AUTOSAR XML (schema 00046)
package /ComponentTypes
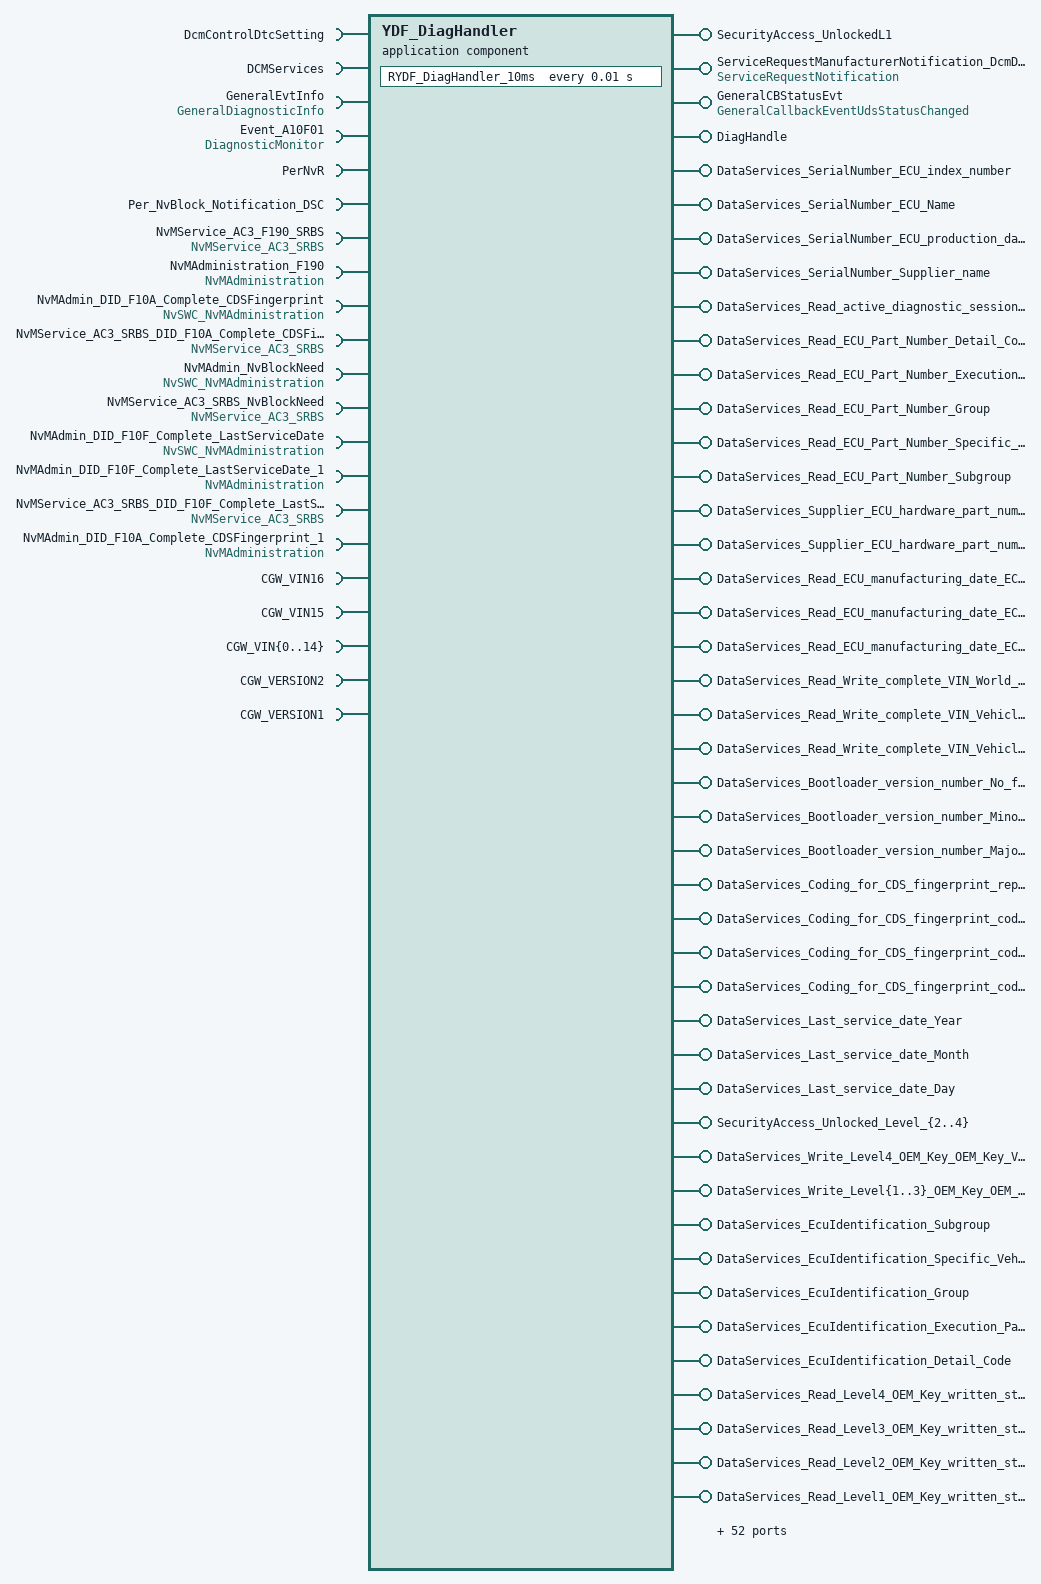
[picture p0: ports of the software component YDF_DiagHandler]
  application sw component type YDF_DiagHandler
    require port DcmControlDtcSetting: mode-switch-receiver-com-spec=DcmControlDtcSetting, required-interface=DcmControlDtcSetting
    require port DCMServices: required-interface=DCMServices
      required-com-specs:
        GetActiveProtocol
        GetSesCtrlType
        ResetToDefaultSession
        GetSecurityLevel
        SetActiveDiagnostic
        GetRequestKind
    provide port SecurityAccess_UnlockedL1: provided-com-specs=[{operation=GetSeed, queue-length=1}, {operation=CompareKey, queue-length=1}], provided-interface=SecurityAccess_UnlockedL1
    provide port ServiceRequestManufacturerNotification_DcmDslServiceRequestManufacturerNotification: provided-com-specs=[{operation=Indication, queue-length=1}, {operation=Confirmation, queue-length=1}], provided-interface=ServiceRequestNotification
    provide port GeneralCBStatusEvt: server-com-spec{operation=GeneralCallbackEventUdsStatusChanged, queue-length=1}, provided-interface=GeneralCallbackEventUdsStatusChanged
    require port GeneralEvtInfo: required-interface=GeneralDiagnosticInfo
      required-com-specs:
        GetEventUdsStatus
        GetEventStatus
        GetEventFailed
        GetEventTested
        GetDTCOfEvent
        GetFaultDetectionCounter
        GetEventFreezeFrameDataEx
        GetEventExtendedDataRecordEx
        GetEventEnableCondition
        GetDebouncingOfEvent
        GetMonitorStatus
    require port Event_A10F01: required-interface=DiagnosticMonitor
      required-com-specs:
        SetEventStatus
        ResetEventStatus
        ResetEventDebounceStatus
        GetEventUdsStatus
        GetEventStatus
        GetEventFailed
        GetEventTested
        GetDTCOfEvent
        GetFaultDetectionCounter
        GetEventFreezeFrameDataEx
        GetEventExtendedDataRecordEx
    provide port DiagHandle: provided-com-specs=[{operation=SetEventSts, queue-length=1}, {operation=GetEventSts, queue-length=1}], provided-interface=DiagHandle
    require port PerNvR: required-com-specs=[WriteRequest, ReadRequest], required-interface=PerNvR
    require port Per_NvBlock_Notification_DSC: nonqueued-receiver-com-spec{data-element=WriteComplete, enable-update=true, filter=data-filter-type=ALWAYS, init-value=0}, required-interface=Per_NvBlock_Notification_DSC
    28 x provide port:
      DataServices_SerialNumber_ECU_index_number: provided-com-specs=[{operation=ConditionCheckRead, queue-length=1}, {operation=ReadData, queue-length=1}], provided-interface=DataServices_SerialNumber_ECU_index_number
      DataServices_SerialNumber_ECU_Name: provided-com-specs=[{operation=ConditionCheckRead, queue-length=1}, {operation=ReadData, queue-length=1}], provided-interface=DataServices_SerialNumber_ECU_Name
      DataServices_SerialNumber_ECU_production_date_in_DD_MM_YY_format: provided-com-specs=[{operation=ConditionCheckRead, queue-length=1}, {operation=ReadData, queue-length=1}], provided-interface=DataServices_SerialNumber_ECU_production_date_in_DD_MM_YY_format
      DataServices_SerialNumber_Supplier_name: provided-com-specs=[{operation=ConditionCheckRead, queue-length=1}, {operation=ReadData, queue-length=1}], provided-interface=DataServices_SerialNumber_Supplier_name
      DataServices_Read_active_diagnostic_session_Active_diagnostic_session: provided-com-specs=[{operation=ConditionCheckRead, queue-length=1}, {operation=ReadData, queue-length=1}], provided-interface=DataServices_Read_active_diagnostic_session_Active_diagnostic_session
      DataServices_Read_ECU_Part_Number_Detail_Code: provided-com-specs=[{operation=ConditionCheckRead, queue-length=1}, {operation=ReadData, queue-length=1}], provided-interface=DataServices_Read_ECU_Part_Number_Detail_Code
      DataServices_Read_ECU_Part_Number_Execution_Package: provided-com-specs=[{operation=ConditionCheckRead, queue-length=1}, {operation=ReadData, queue-length=1}], provided-interface=DataServices_Read_ECU_Part_Number_Execution_Package
      DataServices_Read_ECU_Part_Number_Group: provided-com-specs=[{operation=ConditionCheckRead, queue-length=1}, {operation=ReadData, queue-length=1}], provided-interface=DataServices_Read_ECU_Part_Number_Group
      DataServices_Read_ECU_Part_Number_Specific_Vehicle_Code_WMI: provided-com-specs=[{operation=ConditionCheckRead, queue-length=1}, {operation=ReadData, queue-length=1}], provided-interface=DataServices_Read_ECU_Part_Number_Specific_Vehicle_Code_WMI
      DataServices_Read_ECU_Part_Number_Subgroup: provided-com-specs=[{operation=ConditionCheckRead, queue-length=1}, {operation=ReadData, queue-length=1}], provided-interface=DataServices_Read_ECU_Part_Number_Subgroup
      DataServices_Supplier_ECU_hardware_part_number_Major_release: provided-com-specs=[{operation=ConditionCheckRead, queue-length=1}, {operation=ReadData, queue-length=1}], provided-interface=DataServices_Supplier_ECU_hardware_part_number_Major_release
      DataServices_Supplier_ECU_hardware_part_number_Changes_in_electronic_components_level: provided-com-specs=[{operation=ConditionCheckRead, queue-length=1}, {operation=ReadData, queue-length=1}], provided-interface=DataServices_Supplier_ECU_hardware_part_number_Changes_in_electronic_components_level
      DataServices_Read_ECU_manufacturing_date_ECU_Manufacturing_Date_Day: provided-com-specs=[{operation=ConditionCheckRead, queue-length=1}, {operation=ReadData, queue-length=1}], provided-interface=DataServices_Read_ECU_manufacturing_date_ECU_Manufacturing_Date_Day
      DataServices_Read_ECU_manufacturing_date_ECU_Manufacturing_Date_Month: provided-com-specs=[{operation=ConditionCheckRead, queue-length=1}, {operation=ReadData, queue-length=1}], provided-interface=DataServices_Read_ECU_manufacturing_date_ECU_Manufacturing_Date_Month
      DataServices_Read_ECU_manufacturing_date_ECU_Manufacturing_Date_Year: provided-com-specs=[{operation=ConditionCheckRead, queue-length=1}, {operation=ReadData, queue-length=1}], provided-interface=DataServices_Read_ECU_manufacturing_date_ECU_Manufacturing_Date_Year
      DataServices_Read_Write_complete_VIN_World_Manufacturers_Identification: provided-interface=DataServices_Read_Write_complete_VIN_World_Manufacturers_Identification
        provided-com-specs:
          operation=WriteData, queue-length=1
          operation=ConditionCheckRead, queue-length=1
          operation=ReadData, queue-length=1
      DataServices_Read_Write_complete_VIN_Vehicle_Identification_Section: provided-interface=DataServices_Read_Write_complete_VIN_Vehicle_Identification_Section
        provided-com-specs:
          operation=WriteData, queue-length=1
          operation=ConditionCheckRead, queue-length=1
          operation=ReadData, queue-length=1
      DataServices_Read_Write_complete_VIN_Vehicle_Description_Section: provided-interface=DataServices_Read_Write_complete_VIN_Vehicle_Description_Section
        provided-com-specs:
          operation=WriteData, queue-length=1
          operation=ConditionCheckRead, queue-length=1
          operation=ReadData, queue-length=1
      DataServices_Bootloader_version_number_No_functional_content_change: provided-com-specs=[{operation=ConditionCheckRead, queue-length=1}, {operation=ReadData, queue-length=1}], provided-interface=DataServices_Bootloader_version_number_No_functional_content_change
      DataServices_Bootloader_version_number_Minor_release: provided-com-specs=[{operation=ConditionCheckRead, queue-length=1}, {operation=ReadData, queue-length=1}], provided-interface=DataServices_Bootloader_version_number_Minor_release
      DataServices_Bootloader_version_number_Major_release: provided-com-specs=[{operation=ConditionCheckRead, queue-length=1}, {operation=ReadData, queue-length=1}], provided-interface=DataServices_Bootloader_version_number_Major_release
      DataServices_Coding_for_CDS_fingerprint_repairShopCodeorTesterSerialNumber_byte_1_27_MSB: provided-interface=DataServices_Coding_for_CDS_fingerprint_repairShopCodeorTesterSerialNumber_byte_1_27_MSB
        provided-com-specs:
          operation=WriteData, queue-length=1
          operation=ConditionCheckRead, queue-length=1
          operation=ReadData, queue-length=1
      DataServices_Coding_for_CDS_fingerprint_codingDate_byte_3_DD: provided-interface=DataServices_Coding_for_CDS_fingerprint_codingDate_byte_3_DD
        provided-com-specs:
          operation=WriteData, queue-length=1
          operation=ConditionCheckRead, queue-length=1
          operation=ReadData, queue-length=1
      DataServices_Coding_for_CDS_fingerprint_codingDate_byte_2_MM: provided-interface=DataServices_Coding_for_CDS_fingerprint_codingDate_byte_2_MM
        provided-com-specs:
          operation=WriteData, queue-length=1
          operation=ConditionCheckRead, queue-length=1
          operation=ReadData, queue-length=1
      DataServices_Coding_for_CDS_fingerprint_codingDate_byte_1_YY: provided-interface=DataServices_Coding_for_CDS_fingerprint_codingDate_byte_1_YY
        provided-com-specs:
          operation=WriteData, queue-length=1
          operation=ConditionCheckRead, queue-length=1
          operation=ReadData, queue-length=1
      DataServices_Last_service_date_Year: provided-interface=DataServices_Last_service_date_Year
        provided-com-specs:
          operation=WriteData, queue-length=1
          operation=ConditionCheckRead, queue-length=1
          operation=ReadData, queue-length=1
      DataServices_Last_service_date_Month: provided-interface=DataServices_Last_service_date_Month
        provided-com-specs:
          operation=WriteData, queue-length=1
          operation=ConditionCheckRead, queue-length=1
          operation=ReadData, queue-length=1
      DataServices_Last_service_date_Day: provided-interface=DataServices_Last_service_date_Day
        provided-com-specs:
          operation=WriteData, queue-length=1
          operation=ConditionCheckRead, queue-length=1
          operation=ReadData, queue-length=1
    10 x require port:
      NvMService_AC3_F190_SRBS: required-com-specs=[WriteBlock, SetRamBlockStatus, ReadBlock, InvalidateNvBlock, GetErrorStatus, EraseBlock], required-interface=NvMService_AC3_SRBS
      NvMAdministration_F190: client-com-spec=SetBlockProtection, required-interface=NvMAdministration
      NvMAdmin_DID_F10A_Complete_CDSFingerprint: client-com-spec=SetBlockProtection, required-interface=NvSWC_NvMAdministration
      NvMService_AC3_SRBS_DID_F10A_Complete_CDSFingerprint: required-com-specs=[WriteBlock, SetRamBlockStatus, ReadBlock, InvalidateNvBlock, GetErrorStatus, EraseBlock], required-interface=NvMService_AC3_SRBS
      NvMAdmin_NvBlockNeed: client-com-spec=SetBlockProtection, required-interface=NvSWC_NvMAdministration
      NvMService_AC3_SRBS_NvBlockNeed: required-com-specs=[WriteBlock, SetRamBlockStatus, ReadBlock, InvalidateNvBlock, GetErrorStatus, EraseBlock], required-interface=NvMService_AC3_SRBS
      NvMAdmin_DID_F10F_Complete_LastServiceDate: client-com-spec=SetBlockProtection, required-interface=NvSWC_NvMAdministration
      NvMAdmin_DID_F10F_Complete_LastServiceDate_1: client-com-spec=SetBlockProtection, required-interface=NvMAdministration
      NvMService_AC3_SRBS_DID_F10F_Complete_LastServiceDate: required-com-specs=[WriteBlock, SetRamBlockStatus, ReadBlock, InvalidateNvBlock, GetErrorStatus, EraseBlock], required-interface=NvMService_AC3_SRBS
      NvMAdmin_DID_F10A_Complete_CDSFingerprint_1: client-com-spec=SetBlockProtection, required-interface=NvMAdministration
    62 x provide port:
      SecurityAccess_Unlocked_Level_{2..4}: provided-com-specs=[{operation=CompareKey, queue-length=1}, {operation=GetSeed, queue-length=1}], provided-interface=SecurityAccess_Unlocked_Level_{2..4}
      DataServices_Write_Level4_OEM_Key_OEM_Key_Value: server-com-spec{operation=WriteData, queue-length=1}, provided-interface=DataServices_Write_Level4_OEM_Key_OEM_Key_Value
      DataServices_Write_Level{1..3}_OEM_Key_OEM_Key_Value: server-com-spec{operation=WriteData, queue-length=1}, provided-interface=DataServices_Write_Level{1..3}_OEM_Key_OEM_Key_Value
      DataServices_EcuIdentification_Subgroup: provided-interface=DataServices_EcuIdentification_Subgroup
        provided-com-specs:
          operation=WriteData, queue-length=1
          operation=ConditionCheckRead, queue-length=1
          operation=ReadData, queue-length=1
      DataServices_EcuIdentification_Specific_Vehicle_Code_WMI: provided-interface=DataServices_EcuIdentification_Specific_Vehicle_Code_WMI
        provided-com-specs:
          operation=WriteData, queue-length=1
          operation=ConditionCheckRead, queue-length=1
          operation=ReadData, queue-length=1
      DataServices_EcuIdentification_Group: provided-interface=DataServices_EcuIdentification_Group
        provided-com-specs:
          operation=WriteData, queue-length=1
          operation=ConditionCheckRead, queue-length=1
          operation=ReadData, queue-length=1
      DataServices_EcuIdentification_Execution_Package: provided-interface=DataServices_EcuIdentification_Execution_Package
        provided-com-specs:
          operation=WriteData, queue-length=1
          operation=ConditionCheckRead, queue-length=1
          operation=ReadData, queue-length=1
      DataServices_EcuIdentification_Detail_Code: provided-interface=DataServices_EcuIdentification_Detail_Code
        provided-com-specs:
          operation=WriteData, queue-length=1
          operation=ConditionCheckRead, queue-length=1
          operation=ReadData, queue-length=1
      DataServices_Read_Level4_OEM_Key_written_status_Read_Level4_OEM_Key_rewrite_counter: provided-com-specs=[{operation=ConditionCheckRead, queue-length=1}, {operation=ReadData, queue-length=1}], provided-interface=DataServices_Read_Level4_OEM_Key_written_status_Read_Level4_OEM_Key_rewrite_counter
      DataServices_Read_Level3_OEM_Key_written_status_Read_Level3_OEM_Key_rewrite_counter: provided-com-specs=[{operation=ConditionCheckRead, queue-length=1}, {operation=ReadData, queue-length=1}], provided-interface=DataServices_Read_Level3_OEM_Key_written_status_Read_Level3_OEM_Key_rewrite_counter
      DataServices_Read_Level2_OEM_Key_written_status_Read_Level2_OEM_Key_rewrite_counter: provided-com-specs=[{operation=ConditionCheckRead, queue-length=1}, {operation=ReadData, queue-length=1}], provided-interface=DataServices_Read_Level2_OEM_Key_written_status_Read_Level2_OEM_Key_rewrite_counter
      DataServices_Read_Level1_OEM_Key_written_status_Read_Level1_OEM_Key_rewrite_counter: provided-com-specs=[{operation=ConditionCheckRead, queue-length=1}, {operation=ReadData, queue-length=1}], provided-interface=DataServices_Read_Level1_OEM_Key_written_status_Read_Level1_OEM_Key_rewrite_counter
      DataServices_Read_Vehicle_Security_related_events_Brute_Force_UDS_0x27_servic_Event_occurance_time_Year_5: provided-com-specs=[{operation=ConditionCheckRead, queue-length=1}, {operation=ReadData, queue-length=1}], provided-interface=DataServices_Read_Vehicle_Security_related_events_Brute_Force_UDS_0x27_servic_Event_occurance_time_Year_5
      DataServices_Read_Vehicle_Security_related_events_Brute_Force_UDS_0x27_servic_Event_occurance_time_Year_4: provided-com-specs=[{operation=ConditionCheckRead, queue-length=1}, {operation=ReadData, queue-length=1}], provided-interface=DataServices_Read_Vehicle_Security_related_events_Brute_Force_UDS_0x27_servic_Event_occurance_time_Year_4
      DataServices_Read_Vehicle_Security_related_events_Brute_Force_UDS_0x27_servic_Event_occurance_time_Year_3: provided-com-specs=[{operation=ConditionCheckRead, queue-length=1}, {operation=ReadData, queue-length=1}], provided-interface=DataServices_Read_Vehicle_Security_related_events_Brute_Force_UDS_0x27_servic_Event_occurance_time_Year_3
      DataServices_Read_Vehicle_Security_related_events_Brute_Force_UDS_0x27_servic_Event_occurance_time_Year_2: provided-com-specs=[{operation=ConditionCheckRead, queue-length=1}, {operation=ReadData, queue-length=1}], provided-interface=DataServices_Read_Vehicle_Security_related_events_Brute_Force_UDS_0x27_servic_Event_occurance_time_Year_2
      DataServices_Read_Vehicle_Security_related_events_Brute_Force_UDS_0x27_servic_Event_occurance_time_Year_1: provided-com-specs=[{operation=ConditionCheckRead, queue-length=1}, {operation=ReadData, queue-length=1}], provided-interface=DataServices_Read_Vehicle_Security_related_events_Brute_Force_UDS_0x27_servic_Event_occurance_time_Year_1
      DataServices_Read_Vehicle_Security_related_events_Brute_Force_UDS_0x27_servic_Event_occurance_time_Month_5: provided-com-specs=[{operation=ConditionCheckRead, queue-length=1}, {operation=ReadData, queue-length=1}], provided-interface=DataServices_Read_Vehicle_Security_related_events_Brute_Force_UDS_0x27_servic_Event_occurance_time_Month_5
      DataServices_Read_Vehicle_Security_related_events_Brute_Force_UDS_0x27_servic_Event_occurance_time_Month_4: provided-com-specs=[{operation=ConditionCheckRead, queue-length=1}, {operation=ReadData, queue-length=1}], provided-interface=DataServices_Read_Vehicle_Security_related_events_Brute_Force_UDS_0x27_servic_Event_occurance_time_Month_4
      DataServices_Read_Vehicle_Security_related_events_Brute_Force_UDS_0x27_servic_Event_occurance_time_Month_3: provided-com-specs=[{operation=ConditionCheckRead, queue-length=1}, {operation=ReadData, queue-length=1}], provided-interface=DataServices_Read_Vehicle_Security_related_events_Brute_Force_UDS_0x27_servic_Event_occurance_time_Month_3
      DataServices_Read_Vehicle_Security_related_events_Brute_Force_UDS_0x27_servic_Event_occurance_time_Month_2: provided-com-specs=[{operation=ConditionCheckRead, queue-length=1}, {operation=ReadData, queue-length=1}], provided-interface=DataServices_Read_Vehicle_Security_related_events_Brute_Force_UDS_0x27_servic_Event_occurance_time_Month_2
      DataServices_Read_Vehicle_Security_related_events_Brute_Force_UDS_0x27_servic_Event_occurance_time_Month_1: provided-com-specs=[{operation=ConditionCheckRead, queue-length=1}, {operation=ReadData, queue-length=1}], provided-interface=DataServices_Read_Vehicle_Security_related_events_Brute_Force_UDS_0x27_servic_Event_occurance_time_Month_1
      DataServices_Read_Vehicle_Security_related_events_Brute_Force_UDS_0x27_servic_Event_occurance_time_Day_5: provided-com-specs=[{operation=ConditionCheckRead, queue-length=1}, {operation=ReadData, queue-length=1}], provided-interface=DataServices_Read_Vehicle_Security_related_events_Brute_Force_UDS_0x27_servic_Event_occurance_time_Day_5
      DataServices_Read_Vehicle_Security_related_events_Brute_Force_UDS_0x27_servic_Event_occurance_time_Day_4: provided-com-specs=[{operation=ConditionCheckRead, queue-length=1}, {operation=ReadData, queue-length=1}], provided-interface=DataServices_Read_Vehicle_Security_related_events_Brute_Force_UDS_0x27_servic_Event_occurance_time_Day_4
      DataServices_Read_Vehicle_Security_related_events_Brute_Force_UDS_0x27_servic_Event_occurance_time_Day_3: provided-com-specs=[{operation=ConditionCheckRead, queue-length=1}, {operation=ReadData, queue-length=1}], provided-interface=DataServices_Read_Vehicle_Security_related_events_Brute_Force_UDS_0x27_servic_Event_occurance_time_Day_3
      DataServices_Read_Vehicle_Security_related_events_Brute_Force_UDS_0x27_servic_Event_occurance_time_Day_2: provided-com-specs=[{operation=ConditionCheckRead, queue-length=1}, {operation=ReadData, queue-length=1}], provided-interface=DataServices_Read_Vehicle_Security_related_events_Brute_Force_UDS_0x27_servic_Event_occurance_time_Day_2
      DataServices_Read_Vehicle_Security_related_events_Brute_Force_UDS_0x27_servic_Event_occurance_time_Day_1: provided-com-specs=[{operation=ConditionCheckRead, queue-length=1}, {operation=ReadData, queue-length=1}], provided-interface=DataServices_Read_Vehicle_Security_related_events_Brute_Force_UDS_0x27_servic_Event_occurance_time_Day_1
      DataServices_Read_Vehicle_Security_related_events_Brute_Force_UDS_0x27_servic_Brute_Force_UDS_0x27_service_Event_occurr_0DEE2FAA: provided-com-specs=[{operation=ConditionCheckRead, queue-length=1}, {operation=ReadData, queue-length=1}], provided-interface=DataServices_Read_Vehicle_Security_related_events_Brute_Force_UDS_0x27_servic_Brute_Force_UDS_0x27_service_Event_occurr_0DEE2FAA
      DataServices_Read_Vehicle_Security_related_events_Brute_Force_UDS_0x27_servic_Brute_Force_UDS_0x27_service_5: provided-com-specs=[{operation=ConditionCheckRead, queue-length=1}, {operation=ReadData, queue-length=1}], provided-interface=DataServices_Read_Vehicle_Security_related_events_Brute_Force_UDS_0x27_servic_Brute_Force_UDS_0x27_service_5
      DataServices_Read_Vehicle_Security_related_events_Brute_Force_UDS_0x27_servic_Brute_Force_UDS_0x27_service_4: provided-com-specs=[{operation=ConditionCheckRead, queue-length=1}, {operation=ReadData, queue-length=1}], provided-interface=DataServices_Read_Vehicle_Security_related_events_Brute_Force_UDS_0x27_servic_Brute_Force_UDS_0x27_service_4
      DataServices_Read_Vehicle_Security_related_events_Brute_Force_UDS_0x27_servic_Brute_Force_UDS_0x27_service_3: provided-com-specs=[{operation=ConditionCheckRead, queue-length=1}, {operation=ReadData, queue-length=1}], provided-interface=DataServices_Read_Vehicle_Security_related_events_Brute_Force_UDS_0x27_servic_Brute_Force_UDS_0x27_service_3
      DataServices_Read_Vehicle_Security_related_events_Brute_Force_UDS_0x27_servic_Brute_Force_UDS_0x27_service_2: provided-com-specs=[{operation=ConditionCheckRead, queue-length=1}, {operation=ReadData, queue-length=1}], provided-interface=DataServices_Read_Vehicle_Security_related_events_Brute_Force_UDS_0x27_servic_Brute_Force_UDS_0x27_service_2
      DataServices_Read_Vehicle_Security_related_events_Brute_Force_UDS_0x27_servic_Brute_Force_UDS_0x27_service_1: provided-com-specs=[{operation=ConditionCheckRead, queue-length=1}, {operation=ReadData, queue-length=1}], provided-interface=DataServices_Read_Vehicle_Security_related_events_Brute_Force_UDS_0x27_servic_Brute_Force_UDS_0x27_service_1
      DataServices_Read_Vehicle_Security_related_events_Software_configuration_inte_Software_configuration_integrity_check_fa_B04CEA39: provided-com-specs=[{operation=ConditionCheckRead, queue-length=1}, {operation=ReadData, queue-length=1}], provided-interface=DataServices_Read_Vehicle_Security_related_events_Software_configuration_inte_Software_configuration_integrity_check_fa_B04CEA39
      DataServices_Read_Vehicle_Security_related_events_Software_configuration_inte_Software_configuration_integrity_check_5: provided-com-specs=[{operation=ConditionCheckRead, queue-length=1}, {operation=ReadData, queue-length=1}], provided-interface=DataServices_Read_Vehicle_Security_related_events_Software_configuration_inte_Software_configuration_integrity_check_5
      DataServices_Read_Vehicle_Security_related_events_Software_configuration_inte_Software_configuration_integrity_check_4: provided-com-specs=[{operation=ConditionCheckRead, queue-length=1}, {operation=ReadData, queue-length=1}], provided-interface=DataServices_Read_Vehicle_Security_related_events_Software_configuration_inte_Software_configuration_integrity_check_4
      DataServices_Read_Vehicle_Security_related_events_Software_configuration_inte_Software_configuration_integrity_check_3: provided-com-specs=[{operation=ConditionCheckRead, queue-length=1}, {operation=ReadData, queue-length=1}], provided-interface=DataServices_Read_Vehicle_Security_related_events_Software_configuration_inte_Software_configuration_integrity_check_3
      DataServices_Read_Vehicle_Security_related_events_Software_configuration_inte_Software_configuration_integrity_check_2: provided-com-specs=[{operation=ConditionCheckRead, queue-length=1}, {operation=ReadData, queue-length=1}], provided-interface=DataServices_Read_Vehicle_Security_related_events_Software_configuration_inte_Software_configuration_integrity_check_2
      DataServices_Read_Vehicle_Security_related_events_Software_configuration_inte_Software_configuration_integrity_check_1: provided-com-specs=[{operation=ConditionCheckRead, queue-length=1}, {operation=ReadData, queue-length=1}], provided-interface=DataServices_Read_Vehicle_Security_related_events_Software_configuration_inte_Software_configuration_integrity_check_1
      DataServices_Read_Vehicle_Security_related_events_Software_configuration_inte_Event_occurance_time_Year_5: provided-com-specs=[{operation=ConditionCheckRead, queue-length=1}, {operation=ReadData, queue-length=1}], provided-interface=DataServices_Read_Vehicle_Security_related_events_Software_configuration_inte_Event_occurance_time_Year_5
      DataServices_Read_Vehicle_Security_related_events_Software_configuration_inte_Event_occurance_time_Year_4: provided-com-specs=[{operation=ConditionCheckRead, queue-length=1}, {operation=ReadData, queue-length=1}], provided-interface=DataServices_Read_Vehicle_Security_related_events_Software_configuration_inte_Event_occurance_time_Year_4
      DataServices_Read_Vehicle_Security_related_events_Software_configuration_inte_Event_occurance_time_Year_3: provided-com-specs=[{operation=ConditionCheckRead, queue-length=1}, {operation=ReadData, queue-length=1}], provided-interface=DataServices_Read_Vehicle_Security_related_events_Software_configuration_inte_Event_occurance_time_Year_3
      DataServices_Read_Vehicle_Security_related_events_Software_configuration_inte_Event_occurance_time_Year_2: provided-com-specs=[{operation=ConditionCheckRead, queue-length=1}, {operation=ReadData, queue-length=1}], provided-interface=DataServices_Read_Vehicle_Security_related_events_Software_configuration_inte_Event_occurance_time_Year_2
      DataServices_Read_Vehicle_Security_related_events_Software_configuration_inte_Event_occurance_time_Year_1: provided-com-specs=[{operation=ConditionCheckRead, queue-length=1}, {operation=ReadData, queue-length=1}], provided-interface=DataServices_Read_Vehicle_Security_related_events_Software_configuration_inte_Event_occurance_time_Year_1
      DataServices_Read_Vehicle_Security_related_events_Software_configuration_inte_Event_occurance_time_Month_5: provided-com-specs=[{operation=ConditionCheckRead, queue-length=1}, {operation=ReadData, queue-length=1}], provided-interface=DataServices_Read_Vehicle_Security_related_events_Software_configuration_inte_Event_occurance_time_Month_5
      DataServices_Read_Vehicle_Security_related_events_Software_configuration_inte_Event_occurance_time_Month_4: provided-com-specs=[{operation=ConditionCheckRead, queue-length=1}, {operation=ReadData, queue-length=1}], provided-interface=DataServices_Read_Vehicle_Security_related_events_Software_configuration_inte_Event_occurance_time_Month_4
      DataServices_Read_Vehicle_Security_related_events_Software_configuration_inte_Event_occurance_time_Month_3: provided-com-specs=[{operation=ConditionCheckRead, queue-length=1}, {operation=ReadData, queue-length=1}], provided-interface=DataServices_Read_Vehicle_Security_related_events_Software_configuration_inte_Event_occurance_time_Month_3
      DataServices_Read_Vehicle_Security_related_events_Software_configuration_inte_Event_occurance_time_Month_2: provided-com-specs=[{operation=ConditionCheckRead, queue-length=1}, {operation=ReadData, queue-length=1}], provided-interface=DataServices_Read_Vehicle_Security_related_events_Software_configuration_inte_Event_occurance_time_Month_2
      DataServices_Read_Vehicle_Security_related_events_Software_configuration_inte_Event_occurance_time_Month_1: provided-com-specs=[{operation=ConditionCheckRead, queue-length=1}, {operation=ReadData, queue-length=1}], provided-interface=DataServices_Read_Vehicle_Security_related_events_Software_configuration_inte_Event_occurance_time_Month_1
      DataServices_Read_Vehicle_Security_related_events_Software_configuration_inte_Event_occurance_time_Day_5: provided-com-specs=[{operation=ConditionCheckRead, queue-length=1}, {operation=ReadData, queue-length=1}], provided-interface=DataServices_Read_Vehicle_Security_related_events_Software_configuration_inte_Event_occurance_time_Day_5
      DataServices_Read_Vehicle_Security_related_events_Software_configuration_inte_Event_occurance_time_Day_4: provided-com-specs=[{operation=ConditionCheckRead, queue-length=1}, {operation=ReadData, queue-length=1}], provided-interface=DataServices_Read_Vehicle_Security_related_events_Software_configuration_inte_Event_occurance_time_Day_4
      DataServices_Read_Vehicle_Security_related_events_Software_configuration_inte_Event_occurance_time_Day_3: provided-com-specs=[{operation=ConditionCheckRead, queue-length=1}, {operation=ReadData, queue-length=1}], provided-interface=DataServices_Read_Vehicle_Security_related_events_Software_configuration_inte_Event_occurance_time_Day_3
      DataServices_Read_Vehicle_Security_related_events_Software_configuration_inte_Event_occurance_time_Day_2: provided-com-specs=[{operation=ConditionCheckRead, queue-length=1}, {operation=ReadData, queue-length=1}], provided-interface=DataServices_Read_Vehicle_Security_related_events_Software_configuration_inte_Event_occurance_time_Day_2
      DataServices_Read_Vehicle_Security_related_events_Software_configuration_inte_Event_occurance_time_Day_1: provided-com-specs=[{operation=ConditionCheckRead, queue-length=1}, {operation=ReadData, queue-length=1}], provided-interface=DataServices_Read_Vehicle_Security_related_events_Software_configuration_inte_Event_occurance_time_Day_1
      DataServices_Write_Level4_OEM_Key_CRC: server-com-spec{operation=WriteData, queue-length=1}, provided-interface=DataServices_Write_Level4_OEM_Key_CRC
      DataServices_Write_Level3_OEM_Key_CRC: server-com-spec{operation=WriteData, queue-length=1}, provided-interface=DataServices_Write_Level3_OEM_Key_CRC
      DataServices_Write_Level2_OEM_Key_CRC: server-com-spec{operation=WriteData, queue-length=1}, provided-interface=DataServices_Write_Level2_OEM_Key_CRC
      DataServices_Write_Level1_OEM_Key_CRC: server-com-spec{operation=WriteData, queue-length=1}, provided-interface=DataServices_Write_Level1_OEM_Key_CRC
    19 x require port:
      CGW_VIN16: nonqueued-receiver-com-spec{data-element=CGW_VIN16, filter=data-filter-type=ALWAYS, init-value=0}, required-interface=CGW_VIN16
      CGW_VIN15: nonqueued-receiver-com-spec{data-element=CGW_VIN15, init-value=0}, required-interface=CGW_VIN15
      CGW_VIN{0..14}: nonqueued-receiver-com-spec{data-element=CGW_VIN{0..14}, init-value=0}, required-interface=CGW_VIN{0..14}
      CGW_VERSION2: nonqueued-receiver-com-spec{data-element=CGW_VERSION2, filter=data-filter-type=ALWAYS, init-value=0}, required-interface=CGW_VERSION2
      CGW_VERSION1: nonqueued-receiver-com-spec{data-element=CGW_VERSION1, filter=data-filter-type=ALWAYS, init-value=0}, required-interface=CGW_VERSION1
    6 x provide port, all with provided-com-specs=[{operation=ConditionCheckRead, queue-length=1}, {operation=ReadData, queue-length=1}]:
      DataServices_BSW_version_number_Major_release: provided-interface=DataServices_BSW_version_number_Major_release
      DataServices_BSW_version_number_Minor_release: provided-interface=DataServices_BSW_version_number_Minor_release
      DataServices_BSW_version_number_No_functional_content_change: provided-interface=DataServices_BSW_version_number_No_functional_content_change
      DataServices_DevelopmentData_Country_code: provided-interface=DataServices_DevelopmentData_Country_code
      DataServices_DevelopmentData_Supplier_family_code: provided-interface=DataServices_DevelopmentData_Supplier_family_code
      DataServices_DevelopmentData_Supplier_code: provided-interface=DataServices_DevelopmentData_Supplier_code
    behavior YDF_DiagHandler_InternalBehavior
      init event RYDF_DiagHandler_InitEvent: start-on-event=RYDF_DiagHandler_Init
      timing event TMT_RYDF_DiagHandler_10ms: start-on-event=RYDF_DiagHandler_10ms, period=0.01
      206 x operation invoked event:
        OIT_SecurityAccess_UnlockedL1_CompareKey_SecurityAccess_UnlockedL1_CompareKey: start-on-event=SecurityAccess_UnlockedL1_CompareKey, operation=SecurityAccess_UnlockedL1.CompareKey
        OIT_SecurityAccess_UnlockedL1_GetSeed_SecurityAccess_UnlockedL1_GetSeed: start-on-event=SecurityAccess_UnlockedL1_GetSeed, operation=SecurityAccess_UnlockedL1.GetSeed
        OIT_ServiceRequestManufacturerNotification_DcmDslServiceRequestManufacturerNotification_Confirmation_ServiceRequestManufB5A5EF03: start-on-event=ServiceRequestManufacturerNotification_DcmDslServiceRequestManufacturerNotification_Confirmation, operation=ServiceRequestManufacturerNotification_DcmDslServiceRequestManufacturerNotification.Confirmation
        OIT_ServiceRequestManufacturerNotification_DcmDslServiceRequestManufacturerNotification_Indication_ServiceRequestManufac0656CBDD: start-on-event=ServiceRequestManufacturerNotification_DcmDslServiceRequestManufacturerNotification_Indication, operation=ServiceRequestManufacturerNotification_DcmDslServiceRequestManufacturerNotification.Indication
        OIT_GeneralCBStatusEvt_GeneralCallbackEventUdsStatusChanged_GeneralCBStatusEvt_GeneralCallbackEventUdsStatusChanged: start-on-event=GeneralCBStatusEvt_GeneralCallbackEventUdsStatusChanged, operation=GeneralCBStatusEvt.GeneralCallbackEventUdsStatusChanged
        OIT_DiagHandle_SetEventSts_DiagHandle_SetEventSts: start-on-event=DiagHandle_SetEventSts, operation=DiagHandle.SetEventSts
        OIT_DiagHandle_GetEventSts_DiagHandle_GetEventSts: start-on-event=DiagHandle_GetEventSts, operation=DiagHandle.GetEventSts
        OIT_DataServices_SerialNumber_ECU_Name_ConditionCheckRead_DataServices_SerialNumber_ECU_Name_ConditionCheckRead: start-on-event=DataServices_SerialNumber_ECU_Name_ConditionCheckRead, operation=DataServices_SerialNumber_ECU_Name.ConditionCheckRead
        OIT_DataServices_SerialNumber_ECU_Name_ReadData_DataServices_SerialNumber_ECU_Name_ReadData: start-on-event=DataServices_SerialNumber_ECU_Name_ReadData, operation=DataServices_SerialNumber_ECU_Name.ReadData
        OIT_DataServices_SerialNumber_Supplier_name_ConditionCheckRead_DataServices_SerialNumber_Supplier_name_ConditionCheckRead: start-on-event=DataServices_SerialNumber_Supplier_name_ConditionCheckRead, operation=DataServices_SerialNumber_Supplier_name.ConditionCheckRead
        OIT_DataServices_SerialNumber_Supplier_name_ReadData_DataServices_SerialNumber_Supplier_name_ReadData: start-on-event=DataServices_SerialNumber_Supplier_name_ReadData, operation=DataServices_SerialNumber_Supplier_name.ReadData
        OIT_DataServices_SerialNumber_ECU_production_date_in_DD_MM_YY_format_ConditionCheckRead_DataServices_SerialNumber_ECU_pr44FAFC85: start-on-event=DataServices_SerialNumber_ECU_production_date_in_DD_MM_YY_format_ConditionCheckRead, operation=DataServices_SerialNumber_ECU_production_date_in_DD_MM_YY_format.ConditionCheckRead
        OIT_DataServices_SerialNumber_ECU_production_date_in_DD_MM_YY_format_ReadData_DataServices_SerialNumber_ECU_production_d2FB83547: start-on-event=DataServices_SerialNumber_ECU_production_date_in_DD_MM_YY_format_ReadData, operation=DataServices_SerialNumber_ECU_production_date_in_DD_MM_YY_format.ReadData
        OIT_DataServices_SerialNumber_ECU_index_number_ConditionCheckRead_DataServices_SerialNumber_ECU_index_number_ConditionCheckRead: start-on-event=DataServices_SerialNumber_ECU_index_number_ConditionCheckRead, operation=DataServices_SerialNumber_ECU_index_number.ConditionCheckRead
        OIT_DataServices_SerialNumber_ECU_index_number_ReadData_DataServices_SerialNumber_ECU_index_number_ReadData: start-on-event=DataServices_SerialNumber_ECU_index_number_ReadData, operation=DataServices_SerialNumber_ECU_index_number.ReadData
        OIT_DataServices_Read_active_diagnostic_session_Active_diagnostic_session_ConditionCheckRead_DataServices_Read_active_diB49FB7AF: start-on-event=DataServices_Read_active_diagnostic_session_Active_diagnostic_session_ConditionCheckRead, operation=DataServices_Read_active_diagnostic_session_Active_diagnostic_session.ConditionCheckRead
        OIT_DataServices_Read_active_diagnostic_session_Active_diagnostic_session_ReadData_DataServices_Read_active_diagnostic_s46D8753B: start-on-event=DataServices_Read_active_diagnostic_session_Active_diagnostic_session_ReadData, operation=DataServices_Read_active_diagnostic_session_Active_diagnostic_session.ReadData
        OIT_DataServices_Read_ECU_Part_Number_Subgroup_ConditionCheckRead_DataServices_Read_ECU_Part_Number_Subgroup_ConditionCheckRead: start-on-event=DataServices_Read_ECU_Part_Number_Subgroup_ConditionCheckRead, operation=DataServices_Read_ECU_Part_Number_Subgroup.ConditionCheckRead
        OIT_DataServices_Read_ECU_Part_Number_Subgroup_ReadData_DataServices_Read_ECU_Part_Number_Subgroup_ReadData: start-on-event=DataServices_Read_ECU_Part_Number_Subgroup_ReadData, operation=DataServices_Read_ECU_Part_Number_Subgroup.ReadData
        OIT_DataServices_Read_ECU_Part_Number_Specific_Vehicle_Code_WMI_ConditionCheckRead_DataServices_Read_ECU_Part_Number_Spe426E84EB: start-on-event=DataServices_Read_ECU_Part_Number_Specific_Vehicle_Code_WMI_ConditionCheckRead, operation=DataServices_Read_ECU_Part_Number_Specific_Vehicle_Code_WMI.ConditionCheckRead
        OIT_DataServices_Read_ECU_Part_Number_Specific_Vehicle_Code_WMI_ReadData_DataServices_Read_ECU_Part_Number_Specific_Vehi316D5894: start-on-event=DataServices_Read_ECU_Part_Number_Specific_Vehicle_Code_WMI_ReadData, operation=DataServices_Read_ECU_Part_Number_Specific_Vehicle_Code_WMI.ReadData
        OIT_DataServices_Read_ECU_Part_Number_Detail_Code_ConditionCheckRead_DataServices_Read_ECU_Part_Number_Detail_Code_CondiF64CCC53: start-on-event=DataServices_Read_ECU_Part_Number_Detail_Code_ConditionCheckRead, operation=DataServices_Read_ECU_Part_Number_Detail_Code.ConditionCheckRead
        OIT_DataServices_Read_ECU_Part_Number_Detail_Code_ReadData_DataServices_Read_ECU_Part_Number_Detail_Code_ReadData: start-on-event=DataServices_Read_ECU_Part_Number_Detail_Code_ReadData, operation=DataServices_Read_ECU_Part_Number_Detail_Code.ReadData
        OIT_DataServices_Read_ECU_Part_Number_Execution_Package_ConditionCheckRead_DataServices_Read_ECU_Part_Number_Execution_P90DFECBE: start-on-event=DataServices_Read_ECU_Part_Number_Execution_Package_ConditionCheckRead, operation=DataServices_Read_ECU_Part_Number_Execution_Package.ConditionCheckRead
        OIT_DataServices_Read_ECU_Part_Number_Execution_Package_ReadData_DataServices_Read_ECU_Part_Number_Execution_Package_ReadData: start-on-event=DataServices_Read_ECU_Part_Number_Execution_Package_ReadData, operation=DataServices_Read_ECU_Part_Number_Execution_Package.ReadData
        OIT_DataServices_Read_ECU_Part_Number_Group_ConditionCheckRead_DataServices_Read_ECU_Part_Number_Group_ConditionCheckRead: start-on-event=DataServices_Read_ECU_Part_Number_Group_ConditionCheckRead, operation=DataServices_Read_ECU_Part_Number_Group.ConditionCheckRead
        OIT_DataServices_Read_ECU_Part_Number_Group_ReadData_DataServices_Read_ECU_Part_Number_Group_ReadData: start-on-event=DataServices_Read_ECU_Part_Number_Group_ReadData, operation=DataServices_Read_ECU_Part_Number_Group.ReadData
        OIT_DataServices_Supplier_ECU_hardware_part_number_Major_release_ConditionCheckRead_DataServices_Supplier_ECU_hardware_p96918959: start-on-event=DataServices_Supplier_ECU_hardware_part_number_Major_release_ConditionCheckRead, operation=DataServices_Supplier_ECU_hardware_part_number_Major_release.ConditionCheckRead
        OIT_DataServices_Supplier_ECU_hardware_part_number_Major_release_ReadData_DataServices_Supplier_ECU_hardware_part_number59738653: start-on-event=DataServices_Supplier_ECU_hardware_part_number_Major_release_ReadData, operation=DataServices_Supplier_ECU_hardware_part_number_Major_release.ReadData
        OIT_DataServices_Supplier_ECU_hardware_part_number_Changes_in_electronic_components_level_ConditionCheckRead_DataServiceF0611B9D: start-on-event=DataServices_Supplier_ECU_hardware_part_number_Changes_in_electronic_components_level_ConditionCheckRead, operation=DataServices_Supplier_ECU_hardware_part_number_Changes_in_electronic_components_level.ConditionCheckRead
        OIT_DataServices_Supplier_ECU_hardware_part_number_Changes_in_electronic_components_level_ReadData_DataServices_Supplier2940180F: start-on-event=DataServices_Supplier_ECU_hardware_part_number_Changes_in_electronic_components_level_ReadData, operation=DataServices_Supplier_ECU_hardware_part_number_Changes_in_electronic_components_level.ReadData
        OIT_DataServices_Read_ECU_manufacturing_date_ECU_Manufacturing_Date_Day_ConditionCheckRead_DataServices_Read_ECU_manufac9EC8DA1F: start-on-event=DataServices_Read_ECU_manufacturing_date_ECU_Manufacturing_Date_Day_ConditionCheckRead, operation=DataServices_Read_ECU_manufacturing_date_ECU_Manufacturing_Date_Day.ConditionCheckRead
        OIT_DataServices_Read_ECU_manufacturing_date_ECU_Manufacturing_Date_Day_ReadData_DataServices_Read_ECU_manufacturing_dat60D2E64F: start-on-event=DataServices_Read_ECU_manufacturing_date_ECU_Manufacturing_Date_Day_ReadData, operation=DataServices_Read_ECU_manufacturing_date_ECU_Manufacturing_Date_Day.ReadData
        OIT_DataServices_Read_ECU_manufacturing_date_ECU_Manufacturing_Date_Month_ConditionCheckRead_DataServices_Read_ECU_manuf213660AB: start-on-event=DataServices_Read_ECU_manufacturing_date_ECU_Manufacturing_Date_Month_ConditionCheckRead, operation=DataServices_Read_ECU_manufacturing_date_ECU_Manufacturing_Date_Month.ConditionCheckRead
        OIT_DataServices_Read_ECU_manufacturing_date_ECU_Manufacturing_Date_Month_ReadData_DataServices_Read_ECU_manufacturing_dF4BA3661: start-on-event=DataServices_Read_ECU_manufacturing_date_ECU_Manufacturing_Date_Month_ReadData, operation=DataServices_Read_ECU_manufacturing_date_ECU_Manufacturing_Date_Month.ReadData
        OIT_DataServices_Read_ECU_manufacturing_date_ECU_Manufacturing_Date_Year_ConditionCheckRead_DataServices_Read_ECU_manufa93305012: start-on-event=DataServices_Read_ECU_manufacturing_date_ECU_Manufacturing_Date_Year_ConditionCheckRead, operation=DataServices_Read_ECU_manufacturing_date_ECU_Manufacturing_Date_Year.ConditionCheckRead
        OIT_DataServices_Read_ECU_manufacturing_date_ECU_Manufacturing_Date_Year_ReadData_DataServices_Read_ECU_manufacturing_da075A8D33: start-on-event=DataServices_Read_ECU_manufacturing_date_ECU_Manufacturing_Date_Year_ReadData, operation=DataServices_Read_ECU_manufacturing_date_ECU_Manufacturing_Date_Year.ReadData
        OIT_DataServices_Read_Write_complete_VIN_Vehicle_Identification_Section_WriteData_DataServices_Read_Write_complete_VIN_VD525E295: start-on-event=DataServices_Read_Write_complete_VIN_Vehicle_Identification_Section_WriteData, operation=DataServices_Read_Write_complete_VIN_Vehicle_Identification_Section.WriteData
        OIT_DataServices_Read_Write_complete_VIN_Vehicle_Identification_Section_ConditionCheckRead_DataServices_Read_Write_compl1E42063A: start-on-event=DataServices_Read_Write_complete_VIN_Vehicle_Identification_Section_ConditionCheckRead, operation=DataServices_Read_Write_complete_VIN_Vehicle_Identification_Section.ConditionCheckRead
        OIT_DataServices_Read_Write_complete_VIN_Vehicle_Identification_Section_ReadData_DataServices_Read_Write_complete_VIN_VeCBA606E0: start-on-event=DataServices_Read_Write_complete_VIN_Vehicle_Identification_Section_ReadData, operation=DataServices_Read_Write_complete_VIN_Vehicle_Identification_Section.ReadData
        OIT_DataServices_Read_Write_complete_VIN_Vehicle_Description_Section_WriteData_DataServices_Read_Write_complete_VIN_Vehi3D5B2B2D: start-on-event=DataServices_Read_Write_complete_VIN_Vehicle_Description_Section_WriteData, operation=DataServices_Read_Write_complete_VIN_Vehicle_Description_Section.WriteData
        OIT_DataServices_Read_Write_complete_VIN_Vehicle_Description_Section_ConditionCheckRead_DataServices_Read_Write_complete95F8F646: start-on-event=DataServices_Read_Write_complete_VIN_Vehicle_Description_Section_ConditionCheckRead, operation=DataServices_Read_Write_complete_VIN_Vehicle_Description_Section.ConditionCheckRead
        OIT_DataServices_Read_Write_complete_VIN_Vehicle_Description_Section_ReadData_DataServices_Read_Write_complete_VIN_Vehic41F3C89C: start-on-event=DataServices_Read_Write_complete_VIN_Vehicle_Description_Section_ReadData, operation=DataServices_Read_Write_complete_VIN_Vehicle_Description_Section.ReadData
        OIT_DataServices_Read_Write_complete_VIN_World_Manufacturers_Identification_WriteData_DataServices_Read_Write_complete_VC79B143F: start-on-event=DataServices_Read_Write_complete_VIN_World_Manufacturers_Identification_WriteData, operation=DataServices_Read_Write_complete_VIN_World_Manufacturers_Identification.WriteData
        OIT_DataServices_Read_Write_complete_VIN_World_Manufacturers_Identification_ConditionCheckRead_DataServices_Read_Write_c794DF9F7: start-on-event=DataServices_Read_Write_complete_VIN_World_Manufacturers_Identification_ConditionCheckRead, operation=DataServices_Read_Write_complete_VIN_World_Manufacturers_Identification.ConditionCheckRead
        OIT_DataServices_Read_Write_complete_VIN_World_Manufacturers_Identification_ReadData_DataServices_Read_Write_complete_VI4EEA54AE: start-on-event=DataServices_Read_Write_complete_VIN_World_Manufacturers_Identification_ReadData, operation=DataServices_Read_Write_complete_VIN_World_Manufacturers_Identification.ReadData
        OIT_DataServices_Bootloader_version_number_Major_release_ConditionCheckRead_DataServices_Bootloader_version_number_MajorFB9C4A83: start-on-event=DataServices_Bootloader_version_number_Major_release_ConditionCheckRead, operation=DataServices_Bootloader_version_number_Major_release.ConditionCheckRead
        OIT_DataServices_Bootloader_version_number_Major_release_ReadData_DataServices_Bootloader_version_number_Major_release_ReadData: start-on-event=DataServices_Bootloader_version_number_Major_release_ReadData, operation=DataServices_Bootloader_version_number_Major_release.ReadData
        OIT_DataServices_Bootloader_version_number_No_functional_content_change_ConditionCheckRead_DataServices_Bootloader_versiC8D761B4: start-on-event=DataServices_Bootloader_version_number_No_functional_content_change_ConditionCheckRead, operation=DataServices_Bootloader_version_number_No_functional_content_change.ConditionCheckRead
        OIT_DataServices_Bootloader_version_number_No_functional_content_change_ReadData_DataServices_Bootloader_version_number_89B9F87D: start-on-event=DataServices_Bootloader_version_number_No_functional_content_change_ReadData, operation=DataServices_Bootloader_version_number_No_functional_content_change.ReadData
        OIT_DataServices_Bootloader_version_number_Minor_release_ConditionCheckRead_DataServices_Bootloader_version_number_Minor8DCEBD84: start-on-event=DataServices_Bootloader_version_number_Minor_release_ConditionCheckRead, operation=DataServices_Bootloader_version_number_Minor_release.ConditionCheckRead
        OIT_DataServices_Bootloader_version_number_Minor_release_ReadData_DataServices_Bootloader_version_number_Minor_release_ReadData: start-on-event=DataServices_Bootloader_version_number_Minor_release_ReadData, operation=DataServices_Bootloader_version_number_Minor_release.ReadData
        OIT_DataServices_Coding_for_CDS_fingerprint_codingDate_byte_1_YY_WriteData_DataServices_Coding_for_CDS_fingerprint_codinD669CD8A: start-on-event=DataServices_Coding_for_CDS_fingerprint_codingDate_byte_1_YY_WriteData, operation=DataServices_Coding_for_CDS_fingerprint_codingDate_byte_1_YY.WriteData
        OIT_DataServices_Coding_for_CDS_fingerprint_codingDate_byte_1_YY_ConditionCheckRead_DataServices_Coding_for_CDS_fingerpr8BC391BA: start-on-event=DataServices_Coding_for_CDS_fingerprint_codingDate_byte_1_YY_ConditionCheckRead, operation=DataServices_Coding_for_CDS_fingerprint_codingDate_byte_1_YY.ConditionCheckRead
        OIT_DataServices_Coding_for_CDS_fingerprint_codingDate_byte_1_YY_ReadData_DataServices_Coding_for_CDS_fingerprint_coding2B4017FD: start-on-event=DataServices_Coding_for_CDS_fingerprint_codingDate_byte_1_YY_ReadData, operation=DataServices_Coding_for_CDS_fingerprint_codingDate_byte_1_YY.ReadData
        OIT_DataServices_Coding_for_CDS_fingerprint_codingDate_byte_3_DD_WriteData_DataServices_Coding_for_CDS_fingerprint_codin1BE9EBC8: start-on-event=DataServices_Coding_for_CDS_fingerprint_codingDate_byte_3_DD_WriteData, operation=DataServices_Coding_for_CDS_fingerprint_codingDate_byte_3_DD.WriteData
        OIT_DataServices_Coding_for_CDS_fingerprint_codingDate_byte_3_DD_ConditionCheckRead_DataServices_Coding_for_CDS_fingerpr60774A27: start-on-event=DataServices_Coding_for_CDS_fingerprint_codingDate_byte_3_DD_ConditionCheckRead, operation=DataServices_Coding_for_CDS_fingerprint_codingDate_byte_3_DD.ConditionCheckRead
        OIT_DataServices_Coding_for_CDS_fingerprint_codingDate_byte_3_DD_ReadData_DataServices_Coding_for_CDS_fingerprint_codingD7AEC0B7: start-on-event=DataServices_Coding_for_CDS_fingerprint_codingDate_byte_3_DD_ReadData, operation=DataServices_Coding_for_CDS_fingerprint_codingDate_byte_3_DD.ReadData
        OIT_DataServices_Coding_for_CDS_fingerprint_repairShopCodeorTesterSerialNumber_byte_1_27_MSB_WriteData_DataServices_Codi63C9ABC8: start-on-event=DataServices_Coding_for_CDS_fingerprint_repairShopCodeorTesterSerialNumber_byte_1_27_MSB_WriteData, operation=DataServices_Coding_for_CDS_fingerprint_repairShopCodeorTesterSerialNumber_byte_1_27_MSB.WriteData
        OIT_DataServices_Coding_for_CDS_fingerprint_repairShopCodeorTesterSerialNumber_byte_1_27_MSB_ConditionCheckRead_DataServ02BB341A: start-on-event=DataServices_Coding_for_CDS_fingerprint_repairShopCodeorTesterSerialNumber_byte_1_27_MSB_ConditionCheckRead, operation=DataServices_Coding_for_CDS_fingerprint_repairShopCodeorTesterSerialNumber_byte_1_27_MSB.ConditionCheckRead
        OIT_DataServices_Coding_for_CDS_fingerprint_repairShopCodeorTesterSerialNumber_byte_1_27_MSB_ReadData_DataServices_Codin48C6C15A: start-on-event=DataServices_Coding_for_CDS_fingerprint_repairShopCodeorTesterSerialNumber_byte_1_27_MSB_ReadData, operation=DataServices_Coding_for_CDS_fingerprint_repairShopCodeorTesterSerialNumber_byte_1_27_MSB.ReadData
        OIT_DataServices_Coding_for_CDS_fingerprint_codingDate_byte_2_MM_WriteData_DataServices_Coding_for_CDS_fingerprint_codin6AD9550D: start-on-event=DataServices_Coding_for_CDS_fingerprint_codingDate_byte_2_MM_WriteData, operation=DataServices_Coding_for_CDS_fingerprint_codingDate_byte_2_MM.WriteData
        OIT_DataServices_Coding_for_CDS_fingerprint_codingDate_byte_2_MM_ConditionCheckRead_DataServices_Coding_for_CDS_fingerprFD7E0892: start-on-event=DataServices_Coding_for_CDS_fingerprint_codingDate_byte_2_MM_ConditionCheckRead, operation=DataServices_Coding_for_CDS_fingerprint_codingDate_byte_2_MM.ConditionCheckRead
        OIT_DataServices_Coding_for_CDS_fingerprint_codingDate_byte_2_MM_ReadData_DataServices_Coding_for_CDS_fingerprint_codingC3295457: start-on-event=DataServices_Coding_for_CDS_fingerprint_codingDate_byte_2_MM_ReadData, operation=DataServices_Coding_for_CDS_fingerprint_codingDate_byte_2_MM.ReadData
        OIT_DataServices_Last_service_date_Month_WriteData_DataServices_Last_service_date_Month_WriteData: start-on-event=DataServices_Last_service_date_Month_WriteData, operation=DataServices_Last_service_date_Month.WriteData
        OIT_DataServices_Last_service_date_Month_ConditionCheckRead_DataServices_Last_service_date_Month_ConditionCheckRead: start-on-event=DataServices_Last_service_date_Month_ConditionCheckRead, operation=DataServices_Last_service_date_Month.ConditionCheckRead
        OIT_DataServices_Last_service_date_Month_ReadData_DataServices_Last_service_date_Month_ReadData: start-on-event=DataServices_Last_service_date_Month_ReadData, operation=DataServices_Last_service_date_Month.ReadData
        OIT_DataServices_Last_service_date_Day_WriteData_DataServices_Last_service_date_Day_WriteData: start-on-event=DataServices_Last_service_date_Day_WriteData, operation=DataServices_Last_service_date_Day.WriteData
        OIT_DataServices_Last_service_date_Day_ConditionCheckRead_DataServices_Last_service_date_Day_ConditionCheckRead: start-on-event=DataServices_Last_service_date_Day_ConditionCheckRead, operation=DataServices_Last_service_date_Day.ConditionCheckRead
        OIT_DataServices_Last_service_date_Day_ReadData_DataServices_Last_service_date_Day_ReadData: start-on-event=DataServices_Last_service_date_Day_ReadData, operation=DataServices_Last_service_date_Day.ReadData
        OIT_DataServices_Last_service_date_Year_WriteData_DataServices_Last_service_date_Year_WriteData: start-on-event=DataServices_Last_service_date_Year_WriteData, operation=DataServices_Last_service_date_Year.WriteData
        OIT_DataServices_Last_service_date_Year_ConditionCheckRead_DataServices_Last_service_date_Year_ConditionCheckRead: start-on-event=DataServices_Last_service_date_Year_ConditionCheckRead, operation=DataServices_Last_service_date_Year.ConditionCheckRead
        OIT_DataServices_Last_service_date_Year_ReadData_DataServices_Last_service_date_Year_ReadData: start-on-event=DataServices_Last_service_date_Year_ReadData, operation=DataServices_Last_service_date_Year.ReadData
        OIT_SecurityAccess_Unlocked_Level_4_CompareKey_SecurityAccess_Unlocked_Level_4_CompareKey: start-on-event=SecurityAccess_Unlocked_Level_4_CompareKey, operation=SecurityAccess_Unlocked_Level_4.CompareKey
        OIT_SecurityAccess_Unlocked_Level_4_GetSeed_SecurityAccess_Unlocked_Level_4_GetSeed: start-on-event=SecurityAccess_Unlocked_Level_4_GetSeed, operation=SecurityAccess_Unlocked_Level_4.GetSeed
        OIT_SecurityAccess_Unlocked_Level_3_CompareKey_SecurityAccess_Unlocked_Level_3_CompareKey: start-on-event=SecurityAccess_Unlocked_Level_3_CompareKey, operation=SecurityAccess_Unlocked_Level_3.CompareKey
        OIT_SecurityAccess_Unlocked_Level_3_GetSeed_SecurityAccess_Unlocked_Level_3_GetSeed: start-on-event=SecurityAccess_Unlocked_Level_3_GetSeed, operation=SecurityAccess_Unlocked_Level_3.GetSeed
        OIT_SecurityAccess_Unlocked_Level_2_CompareKey_SecurityAccess_Unlocked_Level_2_CompareKey: start-on-event=SecurityAccess_Unlocked_Level_2_CompareKey, operation=SecurityAccess_Unlocked_Level_2.CompareKey
        OIT_SecurityAccess_Unlocked_Level_2_GetSeed_SecurityAccess_Unlocked_Level_2_GetSeed: start-on-event=SecurityAccess_Unlocked_Level_2_GetSeed, operation=SecurityAccess_Unlocked_Level_2.GetSeed
        OIT_DataServices_Write_Level2_OEM_Key_OEM_Key_Value_WriteData_DataServices_Write_Level2_OEM_Key_OEM_Key_Value_WriteData: start-on-event=DataServices_Write_Level2_OEM_Key_OEM_Key_Value_WriteData, operation=DataServices_Write_Level2_OEM_Key_OEM_Key_Value.WriteData
        OIT_DataServices_Write_Level4_OEM_Key_OEM_Key_Value_WriteData_DataServices_Write_Level4_OEM_Key_OEM_Key_Value_WriteData: start-on-event=DataServices_Write_Level4_OEM_Key_OEM_Key_Value_WriteData, operation=DataServices_Write_Level4_OEM_Key_OEM_Key_Value.WriteData
        OIT_DataServices_Write_Level3_OEM_Key_OEM_Key_Value_WriteData_DataServices_Write_Level3_OEM_Key_OEM_Key_Value_WriteData: start-on-event=DataServices_Write_Level3_OEM_Key_OEM_Key_Value_WriteData, operation=DataServices_Write_Level3_OEM_Key_OEM_Key_Value.WriteData
        OIT_DataServices_Write_Level1_OEM_Key_OEM_Key_Value_WriteData_DataServices_Write_Level1_OEM_Key_OEM_Key_Value_WriteData: start-on-event=DataServices_Write_Level1_OEM_Key_OEM_Key_Value_WriteData, operation=DataServices_Write_Level1_OEM_Key_OEM_Key_Value.WriteData
        OIT_DataServices_EcuIdentification_Group_WriteData_DataServices_EcuIdentification_Group_WriteData: start-on-event=DataServices_EcuIdentification_Group_WriteData, operation=DataServices_EcuIdentification_Group.WriteData
        OIT_DataServices_EcuIdentification_Group_ConditionCheckRead_DataServices_EcuIdentification_Group_ConditionCheckRead: start-on-event=DataServices_EcuIdentification_Group_ConditionCheckRead, operation=DataServices_EcuIdentification_Group.ConditionCheckRead
        OIT_DataServices_EcuIdentification_Group_ReadData_DataServices_EcuIdentification_Group_ReadData: start-on-event=DataServices_EcuIdentification_Group_ReadData, operation=DataServices_EcuIdentification_Group.ReadData
        OIT_DataServices_EcuIdentification_Execution_Package_WriteData_DataServices_EcuIdentification_Execution_Package_WriteData: start-on-event=DataServices_EcuIdentification_Execution_Package_WriteData, operation=DataServices_EcuIdentification_Execution_Package.WriteData
        OIT_DataServices_EcuIdentification_Execution_Package_ConditionCheckRead_DataServices_EcuIdentification_Execution_PackageD30D255E: start-on-event=DataServices_EcuIdentification_Execution_Package_ConditionCheckRead, operation=DataServices_EcuIdentification_Execution_Package.ConditionCheckRead
        OIT_DataServices_EcuIdentification_Execution_Package_ReadData_DataServices_EcuIdentification_Execution_Package_ReadData: start-on-event=DataServices_EcuIdentification_Execution_Package_ReadData, operation=DataServices_EcuIdentification_Execution_Package.ReadData
        OIT_DataServices_EcuIdentification_Detail_Code_WriteData_DataServices_EcuIdentification_Detail_Code_WriteData: start-on-event=DataServices_EcuIdentification_Detail_Code_WriteData, operation=DataServices_EcuIdentification_Detail_Code.WriteData
        OIT_DataServices_EcuIdentification_Detail_Code_ConditionCheckRead_DataServices_EcuIdentification_Detail_Code_ConditionCheckRead: start-on-event=DataServices_EcuIdentification_Detail_Code_ConditionCheckRead, operation=DataServices_EcuIdentification_Detail_Code.ConditionCheckRead
        OIT_DataServices_EcuIdentification_Detail_Code_ReadData_DataServices_EcuIdentification_Detail_Code_ReadData: start-on-event=DataServices_EcuIdentification_Detail_Code_ReadData, operation=DataServices_EcuIdentification_Detail_Code.ReadData
        OIT_DataServices_EcuIdentification_Subgroup_WriteData_DataServices_EcuIdentification_Subgroup_WriteData: start-on-event=DataServices_EcuIdentification_Subgroup_WriteData, operation=DataServices_EcuIdentification_Subgroup.WriteData
        OIT_DataServices_EcuIdentification_Subgroup_ConditionCheckRead_DataServices_EcuIdentification_Subgroup_ConditionCheckRead: start-on-event=DataServices_EcuIdentification_Subgroup_ConditionCheckRead, operation=DataServices_EcuIdentification_Subgroup.ConditionCheckRead
        OIT_DataServices_EcuIdentification_Subgroup_ReadData_DataServices_EcuIdentification_Subgroup_ReadData: start-on-event=DataServices_EcuIdentification_Subgroup_ReadData, operation=DataServices_EcuIdentification_Subgroup.ReadData
        OIT_DataServices_EcuIdentification_Specific_Vehicle_Code_WMI_WriteData_DataServices_EcuIdentification_Specific_Vehicle_CBF67FBD1: start-on-event=DataServices_EcuIdentification_Specific_Vehicle_Code_WMI_WriteData, operation=DataServices_EcuIdentification_Specific_Vehicle_Code_WMI.WriteData
        OIT_DataServices_EcuIdentification_Specific_Vehicle_Code_WMI_ConditionCheckRead_DataServices_EcuIdentification_Specific_2CA2F3B2: start-on-event=DataServices_EcuIdentification_Specific_Vehicle_Code_WMI_ConditionCheckRead, operation=DataServices_EcuIdentification_Specific_Vehicle_Code_WMI.ConditionCheckRead
        OIT_DataServices_EcuIdentification_Specific_Vehicle_Code_WMI_ReadData_DataServices_EcuIdentification_Specific_Vehicle_CoE563E022: start-on-event=DataServices_EcuIdentification_Specific_Vehicle_Code_WMI_ReadData, operation=DataServices_EcuIdentification_Specific_Vehicle_Code_WMI.ReadData
        OIT_DataServices_Read_Level2_OEM_Key_written_status_Read_Level2_OEM_Key_rewrite_counter_ConditionCheckRead_DataServices_06FB5D77: start-on-event=DataServices_Read_Level2_OEM_Key_written_status_Read_Level2_OEM_Key_rewrite_counter_ConditionCheckRead, operation=DataServices_Read_Level2_OEM_Key_written_status_Read_Level2_OEM_Key_rewrite_counter.ConditionCheckRead
        OIT_DataServices_Read_Level2_OEM_Key_written_status_Read_Level2_OEM_Key_rewrite_counter_ReadData_DataServices_Read_Level7CB9E5DD: start-on-event=DataServices_Read_Level2_OEM_Key_written_status_Read_Level2_OEM_Key_rewrite_counter_ReadData, operation=DataServices_Read_Level2_OEM_Key_written_status_Read_Level2_OEM_Key_rewrite_counter.ReadData
        OIT_DataServices_Read_Level4_OEM_Key_written_status_Read_Level4_OEM_Key_rewrite_counter_ConditionCheckRead_DataServices_47DCC714: start-on-event=DataServices_Read_Level4_OEM_Key_written_status_Read_Level4_OEM_Key_rewrite_counter_ConditionCheckRead, operation=DataServices_Read_Level4_OEM_Key_written_status_Read_Level4_OEM_Key_rewrite_counter.ConditionCheckRead
        OIT_DataServices_Read_Level4_OEM_Key_written_status_Read_Level4_OEM_Key_rewrite_counter_ReadData_DataServices_Read_Level5D76E084: start-on-event=DataServices_Read_Level4_OEM_Key_written_status_Read_Level4_OEM_Key_rewrite_counter_ReadData, operation=DataServices_Read_Level4_OEM_Key_written_status_Read_Level4_OEM_Key_rewrite_counter.ReadData
        OIT_DataServices_Read_Level1_OEM_Key_written_status_Read_Level1_OEM_Key_rewrite_counter_ConditionCheckRead_DataServices_CBD01366: start-on-event=DataServices_Read_Level1_OEM_Key_written_status_Read_Level1_OEM_Key_rewrite_counter_ConditionCheckRead, operation=DataServices_Read_Level1_OEM_Key_written_status_Read_Level1_OEM_Key_rewrite_counter.ConditionCheckRead
        OIT_DataServices_Read_Level1_OEM_Key_written_status_Read_Level1_OEM_Key_rewrite_counter_ReadData_DataServices_Read_Level81E6E451: start-on-event=DataServices_Read_Level1_OEM_Key_written_status_Read_Level1_OEM_Key_rewrite_counter_ReadData, operation=DataServices_Read_Level1_OEM_Key_written_status_Read_Level1_OEM_Key_rewrite_counter.ReadData
        OIT_DataServices_Read_Level3_OEM_Key_written_status_Read_Level3_OEM_Key_rewrite_counter_ConditionCheckRead_DataServices_F4CD6547: start-on-event=DataServices_Read_Level3_OEM_Key_written_status_Read_Level3_OEM_Key_rewrite_counter_ConditionCheckRead, operation=DataServices_Read_Level3_OEM_Key_written_status_Read_Level3_OEM_Key_rewrite_counter.ConditionCheckRead
        OIT_DataServices_Read_Level3_OEM_Key_written_status_Read_Level3_OEM_Key_rewrite_counter_ReadData_DataServices_Read_Level9EA3E766: start-on-event=DataServices_Read_Level3_OEM_Key_written_status_Read_Level3_OEM_Key_rewrite_counter_ReadData, operation=DataServices_Read_Level3_OEM_Key_written_status_Read_Level3_OEM_Key_rewrite_counter.ReadData
        OIT_DataServices_Read_Vehicle_Security_related_events_Brute_Force_UDS_0x27_servic_Event_occurance_time_Month_1_Condition40BB9ED1: start-on-event=DataServices_Read_Vehicle_Security_related_events_Brute_Force_UDS_0x27_servic_Event_occurance_time_Month_1_ConditionCheckRead, operation=DataServices_Read_Vehicle_Security_related_events_Brute_Force_UDS_0x27_servic_Event_occurance_time_Month_1.ConditionCheckRead
        OIT_DataServices_Read_Vehicle_Security_related_events_Brute_Force_UDS_0x27_servic_Event_occurance_time_Month_1_ReadData_7218BDD9: start-on-event=DataServices_Read_Vehicle_Security_related_events_Brute_Force_UDS_0x27_servic_Event_occurance_time_Month_1_ReadData, operation=DataServices_Read_Vehicle_Security_related_events_Brute_Force_UDS_0x27_servic_Event_occurance_time_Month_1.ReadData
        OIT_DataServices_Read_Vehicle_Security_related_events_Brute_Force_UDS_0x27_servic_Event_occurance_time_Day_5_ConditionCh0EF745D3: start-on-event=DataServices_Read_Vehicle_Security_related_events_Brute_Force_UDS_0x27_servic_Event_occurance_time_Day_5_ConditionCheckRead, operation=DataServices_Read_Vehicle_Security_related_events_Brute_Force_UDS_0x27_servic_Event_occurance_time_Day_5.ConditionCheckRead
        OIT_DataServices_Read_Vehicle_Security_related_events_Brute_Force_UDS_0x27_servic_Event_occurance_time_Day_5_ReadData_Da18A2A65B: start-on-event=DataServices_Read_Vehicle_Security_related_events_Brute_Force_UDS_0x27_servic_Event_occurance_time_Day_5_ReadData, operation=DataServices_Read_Vehicle_Security_related_events_Brute_Force_UDS_0x27_servic_Event_occurance_time_Day_5.ReadData
        OIT_DataServices_Read_Vehicle_Security_related_events_Brute_Force_UDS_0x27_servic_Event_occurance_time_Day_1_ConditionChDAC69E7E: start-on-event=DataServices_Read_Vehicle_Security_related_events_Brute_Force_UDS_0x27_servic_Event_occurance_time_Day_1_ConditionCheckRead, operation=DataServices_Read_Vehicle_Security_related_events_Brute_Force_UDS_0x27_servic_Event_occurance_time_Day_1.ConditionCheckRead
        OIT_DataServices_Read_Vehicle_Security_related_events_Brute_Force_UDS_0x27_servic_Event_occurance_time_Day_1_ReadData_Da1A23EA34: start-on-event=DataServices_Read_Vehicle_Security_related_events_Brute_Force_UDS_0x27_servic_Event_occurance_time_Day_1_ReadData, operation=DataServices_Read_Vehicle_Security_related_events_Brute_Force_UDS_0x27_servic_Event_occurance_time_Day_1.ReadData
        OIT_DataServices_Read_Vehicle_Security_related_events_Brute_Force_UDS_0x27_servic_Event_occurance_time_Month_4_Condition5E66E225: start-on-event=DataServices_Read_Vehicle_Security_related_events_Brute_Force_UDS_0x27_servic_Event_occurance_time_Month_4_ConditionCheckRead, operation=DataServices_Read_Vehicle_Security_related_events_Brute_Force_UDS_0x27_servic_Event_occurance_time_Month_4.ConditionCheckRead
        OIT_DataServices_Read_Vehicle_Security_related_events_Brute_Force_UDS_0x27_servic_Event_occurance_time_Month_4_ReadData_5B6624EB: start-on-event=DataServices_Read_Vehicle_Security_related_events_Brute_Force_UDS_0x27_servic_Event_occurance_time_Month_4_ReadData, operation=DataServices_Read_Vehicle_Security_related_events_Brute_Force_UDS_0x27_servic_Event_occurance_time_Month_4.ReadData
        OIT_DataServices_Read_Vehicle_Security_related_events_Brute_Force_UDS_0x27_servic_Event_occurance_time_Year_4_ConditionC625682B4: start-on-event=DataServices_Read_Vehicle_Security_related_events_Brute_Force_UDS_0x27_servic_Event_occurance_time_Year_4_ConditionCheckRead, operation=DataServices_Read_Vehicle_Security_related_events_Brute_Force_UDS_0x27_servic_Event_occurance_time_Year_4.ConditionCheckRead
        OIT_DataServices_Read_Vehicle_Security_related_events_Brute_Force_UDS_0x27_servic_Event_occurance_time_Year_4_ReadData_D9010A38F: start-on-event=DataServices_Read_Vehicle_Security_related_events_Brute_Force_UDS_0x27_servic_Event_occurance_time_Year_4_ReadData, operation=DataServices_Read_Vehicle_Security_related_events_Brute_Force_UDS_0x27_servic_Event_occurance_time_Year_4.ReadData
        OIT_DataServices_Read_Vehicle_Security_related_events_Brute_Force_UDS_0x27_servic_Event_occurance_time_Day_3_ConditionCh5D66F088: start-on-event=DataServices_Read_Vehicle_Security_related_events_Brute_Force_UDS_0x27_servic_Event_occurance_time_Day_3_ConditionCheckRead, operation=DataServices_Read_Vehicle_Security_related_events_Brute_Force_UDS_0x27_servic_Event_occurance_time_Day_3.ConditionCheckRead
        OIT_DataServices_Read_Vehicle_Security_related_events_Brute_Force_UDS_0x27_servic_Event_occurance_time_Day_3_ReadData_DaF6DBCF23: start-on-event=DataServices_Read_Vehicle_Security_related_events_Brute_Force_UDS_0x27_servic_Event_occurance_time_Day_3_ReadData, operation=DataServices_Read_Vehicle_Security_related_events_Brute_Force_UDS_0x27_servic_Event_occurance_time_Day_3.ReadData
        OIT_DataServices_Read_Vehicle_Security_related_events_Brute_Force_UDS_0x27_servic_Brute_Force_UDS_0x27_service_3_Conditi51817AF2: start-on-event=DataServices_Read_Vehicle_Security_related_events_Brute_Force_UDS_0x27_service_3_ConditionCheckRead, operation=DataServices_Read_Vehicle_Security_related_events_Brute_Force_UDS_0x27_servic_Brute_Force_UDS_0x27_service_3.ConditionCheckRead
        OIT_DataServices_Read_Vehicle_Security_related_events_Brute_Force_UDS_0x27_servic_Brute_Force_UDS_0x27_service_3_ReadDatF7D70F03: start-on-event=DataServices_Read_Vehicle_Security_related_events_Brute_Force_UDS_0x27_service_3_ReadData, operation=DataServices_Read_Vehicle_Security_related_events_Brute_Force_UDS_0x27_servic_Brute_Force_UDS_0x27_service_3.ReadData
        OIT_DataServices_Read_Vehicle_Security_related_events_Brute_Force_UDS_0x27_servic_Event_occurance_time_Day_4_ConditionCh4D2772A8: start-on-event=DataServices_Read_Vehicle_Security_related_events_Brute_Force_UDS_0x27_servic_Event_occurance_time_Day_4_ConditionCheckRead, operation=DataServices_Read_Vehicle_Security_related_events_Brute_Force_UDS_0x27_servic_Event_occurance_time_Day_4.ConditionCheckRead
        OIT_DataServices_Read_Vehicle_Security_related_events_Brute_Force_UDS_0x27_servic_Event_occurance_time_Day_4_ReadData_Da836637F0: start-on-event=DataServices_Read_Vehicle_Security_related_events_Brute_Force_UDS_0x27_servic_Event_occurance_time_Day_4_ReadData, operation=DataServices_Read_Vehicle_Security_related_events_Brute_Force_UDS_0x27_servic_Event_occurance_time_Day_4.ReadData
        OIT_DataServices_Read_Vehicle_Security_related_events_Brute_Force_UDS_0x27_servic_Brute_Force_UDS_0x27_service_Event_occ4022114E: start-on-event=DataServices_Read_Vehicle_Security_related_events_Brute_Force_UDS_0x27_service_Event_occurr_0DEE2FAA_ConditionCheckRead, operation=DataServices_Read_Vehicle_Security_related_events_Brute_Force_UDS_0x27_servic_Brute_Force_UDS_0x27_service_Event_occurr_0DEE2FAA.ConditionCheckRead
        OIT_DataServices_Read_Vehicle_Security_related_events_Brute_Force_UDS_0x27_servic_Brute_Force_UDS_0x27_service_Event_occ7C199DEF: start-on-event=DataServices_Read_Vehicle_Security_related_events_Brute_Force_UDS_0x27_service_Event_occurr_0DEE2FAA_ReadData, operation=DataServices_Read_Vehicle_Security_related_events_Brute_Force_UDS_0x27_servic_Brute_Force_UDS_0x27_service_Event_occurr_0DEE2FAA.ReadData
        OIT_DataServices_Read_Vehicle_Security_related_events_Brute_Force_UDS_0x27_servic_Brute_Force_UDS_0x27_service_1_Conditi7EEBC54A: start-on-event=DataServices_Read_Vehicle_Security_related_events_Brute_Force_UDS_0x27_service_1_ConditionCheckRead, operation=DataServices_Read_Vehicle_Security_related_events_Brute_Force_UDS_0x27_servic_Brute_Force_UDS_0x27_service_1.ConditionCheckRead
        OIT_DataServices_Read_Vehicle_Security_related_events_Brute_Force_UDS_0x27_servic_Brute_Force_UDS_0x27_service_1_ReadDat94DD3558: start-on-event=DataServices_Read_Vehicle_Security_related_events_Brute_Force_UDS_0x27_service_1_ReadData, operation=DataServices_Read_Vehicle_Security_related_events_Brute_Force_UDS_0x27_servic_Brute_Force_UDS_0x27_service_1.ReadData
        OIT_DataServices_Read_Vehicle_Security_related_events_Brute_Force_UDS_0x27_servic_Event_occurance_time_Month_5_Condition585FFB41: start-on-event=DataServices_Read_Vehicle_Security_related_events_Brute_Force_UDS_0x27_servic_Event_occurance_time_Month_5_ConditionCheckRead, operation=DataServices_Read_Vehicle_Security_related_events_Brute_Force_UDS_0x27_servic_Event_occurance_time_Month_5.ConditionCheckRead
        OIT_DataServices_Read_Vehicle_Security_related_events_Brute_Force_UDS_0x27_servic_Event_occurance_time_Month_5_ReadData_E5FA5E8E: start-on-event=DataServices_Read_Vehicle_Security_related_events_Brute_Force_UDS_0x27_servic_Event_occurance_time_Month_5_ReadData, operation=DataServices_Read_Vehicle_Security_related_events_Brute_Force_UDS_0x27_servic_Event_occurance_time_Month_5.ReadData
        OIT_DataServices_Read_Vehicle_Security_related_events_Brute_Force_UDS_0x27_servic_Brute_Force_UDS_0x27_service_5_Conditi203EBA3A: start-on-event=DataServices_Read_Vehicle_Security_related_events_Brute_Force_UDS_0x27_service_5_ConditionCheckRead, operation=DataServices_Read_Vehicle_Security_related_events_Brute_Force_UDS_0x27_servic_Brute_Force_UDS_0x27_service_5.ConditionCheckRead
        OIT_DataServices_Read_Vehicle_Security_related_events_Brute_Force_UDS_0x27_servic_Brute_Force_UDS_0x27_service_5_ReadDat52C941EE: start-on-event=DataServices_Read_Vehicle_Security_related_events_Brute_Force_UDS_0x27_service_5_ReadData, operation=DataServices_Read_Vehicle_Security_related_events_Brute_Force_UDS_0x27_servic_Brute_Force_UDS_0x27_service_5.ReadData
        OIT_DataServices_Read_Vehicle_Security_related_events_Brute_Force_UDS_0x27_servic_Event_occurance_time_Year_3_ConditionCD18BC335: start-on-event=DataServices_Read_Vehicle_Security_related_events_Brute_Force_UDS_0x27_servic_Event_occurance_time_Year_3_ConditionCheckRead, operation=DataServices_Read_Vehicle_Security_related_events_Brute_Force_UDS_0x27_servic_Event_occurance_time_Year_3.ConditionCheckRead
        OIT_DataServices_Read_Vehicle_Security_related_events_Brute_Force_UDS_0x27_servic_Event_occurance_time_Year_3_ReadData_D445893E3: start-on-event=DataServices_Read_Vehicle_Security_related_events_Brute_Force_UDS_0x27_servic_Event_occurance_time_Year_3_ReadData, operation=DataServices_Read_Vehicle_Security_related_events_Brute_Force_UDS_0x27_servic_Event_occurance_time_Year_3.ReadData
        OIT_DataServices_Read_Vehicle_Security_related_events_Brute_Force_UDS_0x27_servic_Event_occurance_time_Month_3_Condition4CC9AC19: start-on-event=DataServices_Read_Vehicle_Security_related_events_Brute_Force_UDS_0x27_servic_Event_occurance_time_Month_3_ConditionCheckRead, operation=DataServices_Read_Vehicle_Security_related_events_Brute_Force_UDS_0x27_servic_Event_occurance_time_Month_3.ConditionCheckRead
        OIT_DataServices_Read_Vehicle_Security_related_events_Brute_Force_UDS_0x27_servic_Event_occurance_time_Month_3_ReadData_D4514F52: start-on-event=DataServices_Read_Vehicle_Security_related_events_Brute_Force_UDS_0x27_servic_Event_occurance_time_Month_3_ReadData, operation=DataServices_Read_Vehicle_Security_related_events_Brute_Force_UDS_0x27_servic_Event_occurance_time_Month_3.ReadData
        OIT_DataServices_Read_Vehicle_Security_related_events_Brute_Force_UDS_0x27_servic_Event_occurance_time_Year_1_ConditionCABD84383: start-on-event=DataServices_Read_Vehicle_Security_related_events_Brute_Force_UDS_0x27_servic_Event_occurance_time_Year_1_ConditionCheckRead, operation=DataServices_Read_Vehicle_Security_related_events_Brute_Force_UDS_0x27_servic_Event_occurance_time_Year_1.ConditionCheckRead
        OIT_DataServices_Read_Vehicle_Security_related_events_Brute_Force_UDS_0x27_servic_Event_occurance_time_Year_1_ReadData_D9BFE87FD: start-on-event=DataServices_Read_Vehicle_Security_related_events_Brute_Force_UDS_0x27_servic_Event_occurance_time_Year_1_ReadData, operation=DataServices_Read_Vehicle_Security_related_events_Brute_Force_UDS_0x27_servic_Event_occurance_time_Year_1.ReadData
        OIT_DataServices_Read_Vehicle_Security_related_events_Brute_Force_UDS_0x27_servic_Event_occurance_time_Day_2_ConditionCh1EB6C7F3: start-on-event=DataServices_Read_Vehicle_Security_related_events_Brute_Force_UDS_0x27_servic_Event_occurance_time_Day_2_ConditionCheckRead, operation=DataServices_Read_Vehicle_Security_related_events_Brute_Force_UDS_0x27_servic_Event_occurance_time_Day_2.ConditionCheckRead
        OIT_DataServices_Read_Vehicle_Security_related_events_Brute_Force_UDS_0x27_servic_Event_occurance_time_Day_2_ReadData_Da6D1F5E88: start-on-event=DataServices_Read_Vehicle_Security_related_events_Brute_Force_UDS_0x27_servic_Event_occurance_time_Day_2_ReadData, operation=DataServices_Read_Vehicle_Security_related_events_Brute_Force_UDS_0x27_servic_Event_occurance_time_Day_2.ReadData
        OIT_DataServices_Read_Vehicle_Security_related_events_Brute_Force_UDS_0x27_servic_Brute_Force_UDS_0x27_service_4_Conditi378BE5E6: start-on-event=DataServices_Read_Vehicle_Security_related_events_Brute_Force_UDS_0x27_service_4_ConditionCheckRead, operation=DataServices_Read_Vehicle_Security_related_events_Brute_Force_UDS_0x27_servic_Brute_Force_UDS_0x27_service_4.ConditionCheckRead
        OIT_DataServices_Read_Vehicle_Security_related_events_Brute_Force_UDS_0x27_servic_Brute_Force_UDS_0x27_service_4_ReadDat8EF4DFE3: start-on-event=DataServices_Read_Vehicle_Security_related_events_Brute_Force_UDS_0x27_service_4_ReadData, operation=DataServices_Read_Vehicle_Security_related_events_Brute_Force_UDS_0x27_servic_Brute_Force_UDS_0x27_service_4.ReadData
        OIT_DataServices_Read_Vehicle_Security_related_events_Brute_Force_UDS_0x27_servic_Event_occurance_time_Month_2_Condition4AF0B57D: start-on-event=DataServices_Read_Vehicle_Security_related_events_Brute_Force_UDS_0x27_servic_Event_occurance_time_Month_2_ConditionCheckRead, operation=DataServices_Read_Vehicle_Security_related_events_Brute_Force_UDS_0x27_servic_Event_occurance_time_Month_2.ConditionCheckRead
        OIT_DataServices_Read_Vehicle_Security_related_events_Brute_Force_UDS_0x27_servic_Event_occurance_time_Month_2_ReadData_6ACD3537: start-on-event=DataServices_Read_Vehicle_Security_related_events_Brute_Force_UDS_0x27_servic_Event_occurance_time_Month_2_ReadData, operation=DataServices_Read_Vehicle_Security_related_events_Brute_Force_UDS_0x27_servic_Event_occurance_time_Month_2.ReadData
        OIT_DataServices_Read_Vehicle_Security_related_events_Brute_Force_UDS_0x27_servic_Event_occurance_time_Year_5_ConditionC5F7F42EF: start-on-event=DataServices_Read_Vehicle_Security_related_events_Brute_Force_UDS_0x27_servic_Event_occurance_time_Year_5_ConditionCheckRead, operation=DataServices_Read_Vehicle_Security_related_events_Brute_Force_UDS_0x27_servic_Event_occurance_time_Year_5.ConditionCheckRead
        OIT_DataServices_Read_Vehicle_Security_related_events_Brute_Force_UDS_0x27_servic_Event_occurance_time_Year_5_ReadData_DFFC3A980: start-on-event=DataServices_Read_Vehicle_Security_related_events_Brute_Force_UDS_0x27_servic_Event_occurance_time_Year_5_ReadData, operation=DataServices_Read_Vehicle_Security_related_events_Brute_Force_UDS_0x27_servic_Event_occurance_time_Year_5.ReadData
        OIT_DataServices_Read_Vehicle_Security_related_events_Brute_Force_UDS_0x27_servic_Brute_Force_UDS_0x27_service_2_Conditi4634252E: start-on-event=DataServices_Read_Vehicle_Security_related_events_Brute_Force_UDS_0x27_service_2_ConditionCheckRead, operation=DataServices_Read_Vehicle_Security_related_events_Brute_Force_UDS_0x27_servic_Brute_Force_UDS_0x27_service_2.ConditionCheckRead
        OIT_DataServices_Read_Vehicle_Security_related_events_Brute_Force_UDS_0x27_servic_Brute_Force_UDS_0x27_service_2_ReadDat2BEA910E: start-on-event=DataServices_Read_Vehicle_Security_related_events_Brute_Force_UDS_0x27_service_2_ReadData, operation=DataServices_Read_Vehicle_Security_related_events_Brute_Force_UDS_0x27_servic_Brute_Force_UDS_0x27_service_2.ReadData
        OIT_DataServices_Read_Vehicle_Security_related_events_Brute_Force_UDS_0x27_servic_Event_occurance_time_Year_2_ConditionCECA2036E: start-on-event=DataServices_Read_Vehicle_Security_related_events_Brute_Force_UDS_0x27_servic_Event_occurance_time_Year_2_ConditionCheckRead, operation=DataServices_Read_Vehicle_Security_related_events_Brute_Force_UDS_0x27_servic_Event_occurance_time_Year_2.ConditionCheckRead
        OIT_DataServices_Read_Vehicle_Security_related_events_Brute_Force_UDS_0x27_servic_Event_occurance_time_Year_2_ReadData_D2B8B99EC: start-on-event=DataServices_Read_Vehicle_Security_related_events_Brute_Force_UDS_0x27_servic_Event_occurance_time_Year_2_ReadData, operation=DataServices_Read_Vehicle_Security_related_events_Brute_Force_UDS_0x27_servic_Event_occurance_time_Year_2.ReadData
        OIT_DataServices_Read_Vehicle_Security_related_events_Software_configuration_inte_Event_occurance_time_Month_1_Condition76DEF813: start-on-event=DataServices_Read_Vehicle_Security_related_events_Software_configuration_inte_Event_occurance_time_Month_1_ConditionCheckRead, operation=DataServices_Read_Vehicle_Security_related_events_Software_configuration_inte_Event_occurance_time_Month_1.ConditionCheckRead
        OIT_DataServices_Read_Vehicle_Security_related_events_Software_configuration_inte_Event_occurance_time_Month_1_ReadData_40E1BB4A: start-on-event=DataServices_Read_Vehicle_Security_related_events_Software_configuration_inte_Event_occurance_time_Month_1_ReadData, operation=DataServices_Read_Vehicle_Security_related_events_Software_configuration_inte_Event_occurance_time_Month_1.ReadData
        OIT_DataServices_Read_Vehicle_Security_related_events_Software_configuration_inte_Software_configuration_integrity_checkAA0E66BA: start-on-event=DataServices_Read_Vehicle_Security_related_events_Software_configuration_integrity_check_fa_B04CEA39_ConditionCheckRead, operation=DataServices_Read_Vehicle_Security_related_events_Software_configuration_inte_Software_configuration_integrity_check_fa_B04CEA39.ConditionCheckRead
        OIT_DataServices_Read_Vehicle_Security_related_events_Software_configuration_inte_Software_configuration_integrity_check63FDC6D1: start-on-event=DataServices_Read_Vehicle_Security_related_events_Software_configuration_integrity_check_fa_B04CEA39_ReadData, operation=DataServices_Read_Vehicle_Security_related_events_Software_configuration_inte_Software_configuration_integrity_check_fa_B04CEA39.ReadData
        OIT_DataServices_Read_Vehicle_Security_related_events_Software_configuration_inte_Software_configuration_integrity_check00B33AA5: start-on-event=DataServices_Read_Vehicle_Security_related_events_Software_configuration_integrity_check_3_ConditionCheckRead, operation=DataServices_Read_Vehicle_Security_related_events_Software_configuration_inte_Software_configuration_integrity_check_3.ConditionCheckRead
        OIT_DataServices_Read_Vehicle_Security_related_events_Software_configuration_inte_Software_configuration_integrity_checkB98580E2: start-on-event=DataServices_Read_Vehicle_Security_related_events_Software_configuration_integrity_check_3_ReadData, operation=DataServices_Read_Vehicle_Security_related_events_Software_configuration_inte_Software_configuration_integrity_check_3.ReadData
        OIT_DataServices_Read_Vehicle_Security_related_events_Software_configuration_inte_Event_occurance_time_Year_5_ConditionCF8A512E3: start-on-event=DataServices_Read_Vehicle_Security_related_events_Software_configuration_inte_Event_occurance_time_Year_5_ConditionCheckRead, operation=DataServices_Read_Vehicle_Security_related_events_Software_configuration_inte_Event_occurance_time_Year_5.ConditionCheckRead
        OIT_DataServices_Read_Vehicle_Security_related_events_Software_configuration_inte_Event_occurance_time_Year_5_ReadData_D8CA2E550: start-on-event=DataServices_Read_Vehicle_Security_related_events_Software_configuration_inte_Event_occurance_time_Year_5_ReadData, operation=DataServices_Read_Vehicle_Security_related_events_Software_configuration_inte_Event_occurance_time_Year_5.ReadData
        OIT_DataServices_Read_Vehicle_Security_related_events_Software_configuration_inte_Software_configuration_integrity_check161AFC64: start-on-event=DataServices_Read_Vehicle_Security_related_events_Software_configuration_integrity_check_4_ConditionCheckRead, operation=DataServices_Read_Vehicle_Security_related_events_Software_configuration_inte_Software_configuration_integrity_check_4.ConditionCheckRead
        OIT_DataServices_Read_Vehicle_Security_related_events_Software_configuration_inte_Software_configuration_integrity_check97F1810D: start-on-event=DataServices_Read_Vehicle_Security_related_events_Software_configuration_integrity_check_4_ReadData, operation=DataServices_Read_Vehicle_Security_related_events_Software_configuration_inte_Software_configuration_integrity_check_4.ReadData
        OIT_DataServices_Read_Vehicle_Security_related_events_Software_configuration_inte_Event_occurance_time_Day_3_ConditionCh4BC42B67: start-on-event=DataServices_Read_Vehicle_Security_related_events_Software_configuration_inte_Event_occurance_time_Day_3_ConditionCheckRead, operation=DataServices_Read_Vehicle_Security_related_events_Software_configuration_inte_Event_occurance_time_Day_3.ConditionCheckRead
        OIT_DataServices_Read_Vehicle_Security_related_events_Software_configuration_inte_Event_occurance_time_Day_3_ReadData_Da9327F6B9: start-on-event=DataServices_Read_Vehicle_Security_related_events_Software_configuration_inte_Event_occurance_time_Day_3_ReadData, operation=DataServices_Read_Vehicle_Security_related_events_Software_configuration_inte_Event_occurance_time_Day_3.ReadData
        OIT_DataServices_Read_Vehicle_Security_related_events_Software_configuration_inte_Event_occurance_time_Day_5_ConditionCh18559E3C: start-on-event=DataServices_Read_Vehicle_Security_related_events_Software_configuration_inte_Event_occurance_time_Day_5_ConditionCheckRead, operation=DataServices_Read_Vehicle_Security_related_events_Software_configuration_inte_Event_occurance_time_Day_5.ConditionCheckRead
        OIT_DataServices_Read_Vehicle_Security_related_events_Software_configuration_inte_Event_occurance_time_Day_5_ReadData_Da7D5E9FC1: start-on-event=DataServices_Read_Vehicle_Security_related_events_Software_configuration_inte_Event_occurance_time_Day_5_ReadData, operation=DataServices_Read_Vehicle_Security_related_events_Software_configuration_inte_Event_occurance_time_Day_5.ReadData
        OIT_DataServices_Read_Vehicle_Security_related_events_Software_configuration_inte_Event_occurance_time_Day_1_ConditionChCC644591: start-on-event=DataServices_Read_Vehicle_Security_related_events_Software_configuration_inte_Event_occurance_time_Day_1_ConditionCheckRead, operation=DataServices_Read_Vehicle_Security_related_events_Software_configuration_inte_Event_occurance_time_Day_1.ConditionCheckRead
        OIT_DataServices_Read_Vehicle_Security_related_events_Software_configuration_inte_Event_occurance_time_Day_1_ReadData_Da7FDFD3AE: start-on-event=DataServices_Read_Vehicle_Security_related_events_Software_configuration_inte_Event_occurance_time_Day_1_ReadData, operation=DataServices_Read_Vehicle_Security_related_events_Software_configuration_inte_Event_occurance_time_Day_1.ReadData
        OIT_DataServices_Read_Vehicle_Security_related_events_Software_configuration_inte_Event_occurance_time_Year_3_ConditionC76519339: start-on-event=DataServices_Read_Vehicle_Security_related_events_Software_configuration_inte_Event_occurance_time_Year_3_ConditionCheckRead, operation=DataServices_Read_Vehicle_Security_related_events_Software_configuration_inte_Event_occurance_time_Year_3.ConditionCheckRead
        OIT_DataServices_Read_Vehicle_Security_related_events_Software_configuration_inte_Event_occurance_time_Year_3_ReadData_D3739DF33: start-on-event=DataServices_Read_Vehicle_Security_related_events_Software_configuration_inte_Event_occurance_time_Year_3_ReadData, operation=DataServices_Read_Vehicle_Security_related_events_Software_configuration_inte_Event_occurance_time_Year_3.ReadData
        OIT_DataServices_Read_Vehicle_Security_related_events_Software_configuration_inte_Software_configuration_integrity_checkC09EBBBE: start-on-event=DataServices_Read_Vehicle_Security_related_events_Software_configuration_integrity_check_1_ConditionCheckRead, operation=DataServices_Read_Vehicle_Security_related_events_Software_configuration_inte_Software_configuration_integrity_check_1.ConditionCheckRead
        OIT_DataServices_Read_Vehicle_Security_related_events_Software_configuration_inte_Software_configuration_integrity_checkA6CB5B10: start-on-event=DataServices_Read_Vehicle_Security_related_events_Software_configuration_integrity_check_1_ReadData, operation=DataServices_Read_Vehicle_Security_related_events_Software_configuration_inte_Software_configuration_integrity_check_1.ReadData
        OIT_DataServices_Read_Vehicle_Security_related_events_Software_configuration_inte_Event_occurance_time_Day_2_ConditionCh08141C1C: start-on-event=DataServices_Read_Vehicle_Security_related_events_Software_configuration_inte_Event_occurance_time_Day_2_ConditionCheckRead, operation=DataServices_Read_Vehicle_Security_related_events_Software_configuration_inte_Event_occurance_time_Day_2.ConditionCheckRead
        OIT_DataServices_Read_Vehicle_Security_related_events_Software_configuration_inte_Event_occurance_time_Day_2_ReadData_Da08E36712: start-on-event=DataServices_Read_Vehicle_Security_related_events_Software_configuration_inte_Event_occurance_time_Day_2_ReadData, operation=DataServices_Read_Vehicle_Security_related_events_Software_configuration_inte_Event_occurance_time_Day_2.ReadData
        OIT_DataServices_Read_Vehicle_Security_related_events_Software_configuration_inte_Event_occurance_time_Day_4_ConditionCh5B85A947: start-on-event=DataServices_Read_Vehicle_Security_related_events_Software_configuration_inte_Event_occurance_time_Day_4_ConditionCheckRead, operation=DataServices_Read_Vehicle_Security_related_events_Software_configuration_inte_Event_occurance_time_Day_4.ConditionCheckRead
        OIT_DataServices_Read_Vehicle_Security_related_events_Software_configuration_inte_Event_occurance_time_Day_4_ReadData_DaE69A0E6A: start-on-event=DataServices_Read_Vehicle_Security_related_events_Software_configuration_inte_Event_occurance_time_Day_4_ReadData, operation=DataServices_Read_Vehicle_Security_related_events_Software_configuration_inte_Event_occurance_time_Day_4.ReadData
        OIT_DataServices_Read_Vehicle_Security_related_events_Software_configuration_inte_Event_occurance_time_Month_4_Condition680384E7: start-on-event=DataServices_Read_Vehicle_Security_related_events_Software_configuration_inte_Event_occurance_time_Month_4_ConditionCheckRead, operation=DataServices_Read_Vehicle_Security_related_events_Software_configuration_inte_Event_occurance_time_Month_4.ConditionCheckRead
        OIT_DataServices_Read_Vehicle_Security_related_events_Software_configuration_inte_Event_occurance_time_Month_4_ReadData_699F2278: start-on-event=DataServices_Read_Vehicle_Security_related_events_Software_configuration_inte_Event_occurance_time_Month_4_ReadData, operation=DataServices_Read_Vehicle_Security_related_events_Software_configuration_inte_Event_occurance_time_Month_4.ReadData
        OIT_DataServices_Read_Vehicle_Security_related_events_Software_configuration_inte_Event_occurance_time_Month_5_Condition6E3A9D83: start-on-event=DataServices_Read_Vehicle_Security_related_events_Software_configuration_inte_Event_occurance_time_Month_5_ConditionCheckRead, operation=DataServices_Read_Vehicle_Security_related_events_Software_configuration_inte_Event_occurance_time_Month_5.ConditionCheckRead
        OIT_DataServices_Read_Vehicle_Security_related_events_Software_configuration_inte_Event_occurance_time_Month_5_ReadData_D703581D: start-on-event=DataServices_Read_Vehicle_Security_related_events_Software_configuration_inte_Event_occurance_time_Month_5_ReadData, operation=DataServices_Read_Vehicle_Security_related_events_Software_configuration_inte_Event_occurance_time_Month_5.ReadData
        OIT_DataServices_Read_Vehicle_Security_related_events_Software_configuration_inte_Software_configuration_integrity_check9BB4BFC9: start-on-event=DataServices_Read_Vehicle_Security_related_events_Software_configuration_integrity_check_5_ConditionCheckRead, operation=DataServices_Read_Vehicle_Security_related_events_Software_configuration_inte_Software_configuration_integrity_check_5.ConditionCheckRead
        OIT_DataServices_Read_Vehicle_Security_related_events_Software_configuration_inte_Software_configuration_integrity_check9856ECF4: start-on-event=DataServices_Read_Vehicle_Security_related_events_Software_configuration_integrity_check_5_ReadData, operation=DataServices_Read_Vehicle_Security_related_events_Software_configuration_inte_Software_configuration_integrity_check_5.ReadData
        OIT_DataServices_Read_Vehicle_Security_related_events_Software_configuration_inte_Event_occurance_time_Month_2_Condition7C95D3BF: start-on-event=DataServices_Read_Vehicle_Security_related_events_Software_configuration_inte_Event_occurance_time_Month_2_ConditionCheckRead, operation=DataServices_Read_Vehicle_Security_related_events_Software_configuration_inte_Event_occurance_time_Month_2.ConditionCheckRead
        OIT_DataServices_Read_Vehicle_Security_related_events_Software_configuration_inte_Event_occurance_time_Month_2_ReadData_583433A4: start-on-event=DataServices_Read_Vehicle_Security_related_events_Software_configuration_inte_Event_occurance_time_Month_2_ReadData, operation=DataServices_Read_Vehicle_Security_related_events_Software_configuration_inte_Event_occurance_time_Month_2.ReadData
        OIT_DataServices_Read_Vehicle_Security_related_events_Software_configuration_inte_Software_configuration_integrity_check8D1D7908: start-on-event=DataServices_Read_Vehicle_Security_related_events_Software_configuration_integrity_check_2_ConditionCheckRead, operation=DataServices_Read_Vehicle_Security_related_events_Software_configuration_inte_Software_configuration_integrity_check_2.ConditionCheckRead
        OIT_DataServices_Read_Vehicle_Security_related_events_Software_configuration_inte_Software_configuration_integrity_checkB622ED1B: start-on-event=DataServices_Read_Vehicle_Security_related_events_Software_configuration_integrity_check_2_ReadData, operation=DataServices_Read_Vehicle_Security_related_events_Software_configuration_inte_Software_configuration_integrity_check_2.ReadData
        OIT_DataServices_Read_Vehicle_Security_related_events_Software_configuration_inte_Event_occurance_time_Month_3_Condition7AACCADB: start-on-event=DataServices_Read_Vehicle_Security_related_events_Software_configuration_inte_Event_occurance_time_Month_3_ConditionCheckRead, operation=DataServices_Read_Vehicle_Security_related_events_Software_configuration_inte_Event_occurance_time_Month_3.ConditionCheckRead
        OIT_DataServices_Read_Vehicle_Security_related_events_Software_configuration_inte_Event_occurance_time_Month_3_ReadData_E6A849C1: start-on-event=DataServices_Read_Vehicle_Security_related_events_Software_configuration_inte_Event_occurance_time_Month_3_ReadData, operation=DataServices_Read_Vehicle_Security_related_events_Software_configuration_inte_Event_occurance_time_Month_3.ReadData
        OIT_DataServices_Read_Vehicle_Security_related_events_Software_configuration_inte_Event_occurance_time_Year_1_ConditionC0C02138F: start-on-event=DataServices_Read_Vehicle_Security_related_events_Software_configuration_inte_Event_occurance_time_Year_1_ConditionCheckRead, operation=DataServices_Read_Vehicle_Security_related_events_Software_configuration_inte_Event_occurance_time_Year_1.ConditionCheckRead
        OIT_DataServices_Read_Vehicle_Security_related_events_Software_configuration_inte_Event_occurance_time_Year_1_ReadData_DE89FCB2D: start-on-event=DataServices_Read_Vehicle_Security_related_events_Software_configuration_inte_Event_occurance_time_Year_1_ReadData, operation=DataServices_Read_Vehicle_Security_related_events_Software_configuration_inte_Event_occurance_time_Year_1.ReadData
        OIT_DataServices_Read_Vehicle_Security_related_events_Software_configuration_inte_Event_occurance_time_Year_2_ConditionC4B785362: start-on-event=DataServices_Read_Vehicle_Security_related_events_Software_configuration_inte_Event_occurance_time_Year_2_ConditionCheckRead, operation=DataServices_Read_Vehicle_Security_related_events_Software_configuration_inte_Event_occurance_time_Year_2.ConditionCheckRead
        OIT_DataServices_Read_Vehicle_Security_related_events_Software_configuration_inte_Event_occurance_time_Year_2_ReadData_D58EAD53C: start-on-event=DataServices_Read_Vehicle_Security_related_events_Software_configuration_inte_Event_occurance_time_Year_2_ReadData, operation=DataServices_Read_Vehicle_Security_related_events_Software_configuration_inte_Event_occurance_time_Year_2.ReadData
        OIT_DataServices_Read_Vehicle_Security_related_events_Software_configuration_inte_Event_occurance_time_Year_4_ConditionCC58CD2B8: start-on-event=DataServices_Read_Vehicle_Security_related_events_Software_configuration_inte_Event_occurance_time_Year_4_ConditionCheckRead, operation=DataServices_Read_Vehicle_Security_related_events_Software_configuration_inte_Event_occurance_time_Year_4.ConditionCheckRead
        OIT_DataServices_Read_Vehicle_Security_related_events_Software_configuration_inte_Event_occurance_time_Year_4_ReadData_DE371EF5F: start-on-event=DataServices_Read_Vehicle_Security_related_events_Software_configuration_inte_Event_occurance_time_Year_4_ReadData, operation=DataServices_Read_Vehicle_Security_related_events_Software_configuration_inte_Event_occurance_time_Year_4.ReadData
        OIT_DataServices_Write_Level1_OEM_Key_CRC_WriteData_DataServices_Write_Level1_OEM_Key_CRC_WriteData: start-on-event=DataServices_Write_Level1_OEM_Key_CRC_WriteData, operation=DataServices_Write_Level1_OEM_Key_CRC.WriteData
        OIT_DataServices_Write_Level4_OEM_Key_CRC_WriteData_DataServices_Write_Level4_OEM_Key_CRC_WriteData: start-on-event=DataServices_Write_Level4_OEM_Key_CRC_WriteData, operation=DataServices_Write_Level4_OEM_Key_CRC.WriteData
        OIT_DataServices_Write_Level3_OEM_Key_CRC_WriteData_DataServices_Write_Level3_OEM_Key_CRC_WriteData: start-on-event=DataServices_Write_Level3_OEM_Key_CRC_WriteData, operation=DataServices_Write_Level3_OEM_Key_CRC.WriteData
        OIT_DataServices_Write_Level2_OEM_Key_CRC_WriteData_DataServices_Write_Level2_OEM_Key_CRC_WriteData: start-on-event=DataServices_Write_Level2_OEM_Key_CRC_WriteData, operation=DataServices_Write_Level2_OEM_Key_CRC.WriteData
        OIT_DataServices_BSW_version_number_Minor_release_ConditionCheckRead_DataServices_BSW_version_number_Minor_release_Condi4D46E2AA: start-on-event=DataServices_BSW_version_number_Minor_release_ConditionCheckRead, operation=DataServices_BSW_version_number_Minor_release.ConditionCheckRead
        OIT_DataServices_BSW_version_number_Minor_release_ReadData_DataServices_BSW_version_number_Minor_release_ReadData: start-on-event=DataServices_BSW_version_number_Minor_release_ReadData, operation=DataServices_BSW_version_number_Minor_release.ReadData
        OIT_DataServices_BSW_version_number_No_functional_content_change_ConditionCheckRead_DataServices_BSW_version_number_No_f40BB40FD: start-on-event=DataServices_BSW_version_number_No_functional_content_change_ConditionCheckRead, operation=DataServices_BSW_version_number_No_functional_content_change.ConditionCheckRead
        OIT_DataServices_BSW_version_number_No_functional_content_change_ReadData_DataServices_BSW_version_number_No_functional_2B0B0C56: start-on-event=DataServices_BSW_version_number_No_functional_content_change_ReadData, operation=DataServices_BSW_version_number_No_functional_content_change.ReadData
        OIT_DataServices_BSW_version_number_Major_release_ConditionCheckRead_DataServices_BSW_version_number_Major_release_CondiC78259A6: start-on-event=DataServices_BSW_version_number_Major_release_ConditionCheckRead, operation=DataServices_BSW_version_number_Major_release.ConditionCheckRead
        OIT_DataServices_BSW_version_number_Major_release_ReadData_DataServices_BSW_version_number_Major_release_ReadData: start-on-event=DataServices_BSW_version_number_Major_release_ReadData, operation=DataServices_BSW_version_number_Major_release.ReadData
        OIT_DataServices_DevelopmentData_Supplier_family_code_ConditionCheckRead_DataServices_DevelopmentData_Supplier_family_co12DE5759: start-on-event=DataServices_DevelopmentData_Supplier_family_code_ConditionCheckRead, operation=DataServices_DevelopmentData_Supplier_family_code.ConditionCheckRead
        OIT_DataServices_DevelopmentData_Supplier_family_code_ReadData_DataServices_DevelopmentData_Supplier_family_code_ReadData: start-on-event=DataServices_DevelopmentData_Supplier_family_code_ReadData, operation=DataServices_DevelopmentData_Supplier_family_code.ReadData
        OIT_DataServices_DevelopmentData_Country_code_ConditionCheckRead_DataServices_DevelopmentData_Country_code_ConditionCheckRead: start-on-event=DataServices_DevelopmentData_Country_code_ConditionCheckRead, operation=DataServices_DevelopmentData_Country_code.ConditionCheckRead
        OIT_DataServices_DevelopmentData_Country_code_ReadData_DataServices_DevelopmentData_Country_code_ReadData: start-on-event=DataServices_DevelopmentData_Country_code_ReadData, operation=DataServices_DevelopmentData_Country_code.ReadData
        OIT_DataServices_DevelopmentData_Supplier_code_ConditionCheckRead_DataServices_DevelopmentData_Supplier_code_ConditionCheckRead: start-on-event=DataServices_DevelopmentData_Supplier_code_ConditionCheckRead, operation=DataServices_DevelopmentData_Supplier_code.ConditionCheckRead
        OIT_DataServices_DevelopmentData_Supplier_code_ReadData_DataServices_DevelopmentData_Supplier_code_ReadData: start-on-event=DataServices_DevelopmentData_Supplier_code_ReadData, operation=DataServices_DevelopmentData_Supplier_code.ReadData
      213 x runnable:
        RYDF_DiagHandler_Init
        RYDF_DiagHandler_10ms
          data-receive-point-by-arguments:
            20 x access:
              REC_Per_NvBlock_Notification_DSC_WriteComplete: accessed-variable=Per_NvBlock_Notification_DSC.WriteComplete
              REC_CGW_VIN0_CGW_VIN0: accessed-variable=CGW_VIN0.CGW_VIN0
              REC_CGW_VIN1_CGW_VIN1: accessed-variable=CGW_VIN1.CGW_VIN1
              REC_CGW_VIN{10..16}_CGW_VIN{10..16}: accessed-variable=CGW_VIN{10..16}.CGW_VIN{10..16}
              REC_CGW_VIN{2..9}_CGW_VIN{2..9}: accessed-variable=CGW_VIN{2..9}.CGW_VIN{2..9}
              REC_CGW_VERSION1_CGW_VERSION1: accessed-variable=CGW_VERSION1.CGW_VERSION1
              REC_CGW_VERSION2_CGW_VERSION2: accessed-variable=CGW_VERSION2.CGW_VERSION2
          5 x sync call:
            SC_Event_A10F01_SetEventStatus: operation=Event_A10F01.SetEventStatus
            SC_GeneralEvtInfo_GetEventStatus: operation=GeneralEvtInfo.GetEventStatus
            SC_Event_A10F01_GetEventStatus: operation=Event_A10F01.GetEventStatus
            SC_PerNvR_WriteRequest: operation=PerNvR.WriteRequest
            SC_PerNvR_ReadRequest: operation=PerNvR.ReadRequest
        DataServices_Data_ACCUnavailable_Read_ConditionCheckRead
        DataServices_Data_ACCUnavailable_Read_ReadData
        DataServices_Data_DID_Date_Time_Read_ConditionCheckRead
        DataServices_Data_DID_Date_Time_Read_ReadData
        RoutineServices_Routine_CalculateSoftwareVerificationNumber_Start_Start
        SecurityAccess_UnlockedL1_CompareKey
        SecurityAccess_UnlockedL1_GetSeed
        ServiceRequestManufacturerNotification_DcmDslServiceRequestManufacturerNotification_Confirmation
        ServiceRequestManufacturerNotification_DcmDslServiceRequestManufacturerNotification_Indication
        GeneralCBStatusEvt_GeneralCallbackEventUdsStatusChanged
        DiagHandle_SetEventSts
        DiagHandle_GetEventSts
        DataServices_SerialNumber_ECU_Name_ConditionCheckRead
        DataServices_SerialNumber_ECU_Name_ReadData
        DataServices_SerialNumber_Supplier_name_ConditionCheckRead
        DataServices_SerialNumber_Supplier_name_ReadData
        DataServices_SerialNumber_ECU_production_date_in_DD_MM_YY_format_ConditionCheckRead
        DataServices_SerialNumber_ECU_production_date_in_DD_MM_YY_format_ReadData
        DataServices_SerialNumber_ECU_index_number_ConditionCheckRead
        DataServices_SerialNumber_ECU_index_number_ReadData
        DataServices_Read_active_diagnostic_session_Active_diagnostic_session_ConditionCheckRead
        DataServices_Read_active_diagnostic_session_Active_diagnostic_session_ReadData
        DataServices_Read_ECU_Part_Number_Subgroup_ConditionCheckRead
        DataServices_Read_ECU_Part_Number_Subgroup_ReadData
        DataServices_Read_ECU_Part_Number_Specific_Vehicle_Code_WMI_ConditionCheckRead
        DataServices_Read_ECU_Part_Number_Specific_Vehicle_Code_WMI_ReadData
        DataServices_Read_ECU_Part_Number_Detail_Code_ConditionCheckRead
        DataServices_Read_ECU_Part_Number_Detail_Code_ReadData
        DataServices_Read_ECU_Part_Number_Execution_Package_ConditionCheckRead
        DataServices_Read_ECU_Part_Number_Execution_Package_ReadData
        DataServices_Read_ECU_Part_Number_Group_ConditionCheckRead
        DataServices_Read_ECU_Part_Number_Group_ReadData
        DataServices_Supplier_ECU_hardware_part_number_Major_release_ConditionCheckRead
        DataServices_Supplier_ECU_hardware_part_number_Major_release_ReadData
        DataServices_Supplier_ECU_hardware_part_number_Changes_in_electronic_components_level_ConditionCheckRead
        DataServices_Supplier_ECU_hardware_part_number_Changes_in_electronic_components_level_ReadData
        DataServices_Read_ECU_manufacturing_date_ECU_Manufacturing_Date_Day_ConditionCheckRead
        DataServices_Read_ECU_manufacturing_date_ECU_Manufacturing_Date_Day_ReadData
        DataServices_Read_ECU_manufacturing_date_ECU_Manufacturing_Date_Month_ConditionCheckRead
        DataServices_Read_ECU_manufacturing_date_ECU_Manufacturing_Date_Month_ReadData
        DataServices_Read_ECU_manufacturing_date_ECU_Manufacturing_Date_Year_ConditionCheckRead
        DataServices_Read_ECU_manufacturing_date_ECU_Manufacturing_Date_Year_ReadData
        DataServices_Read_Write_complete_VIN_Vehicle_Identification_Section_WriteData
        DataServices_Read_Write_complete_VIN_Vehicle_Identification_Section_ConditionCheckRead
        DataServices_Read_Write_complete_VIN_Vehicle_Identification_Section_ReadData
        DataServices_Read_Write_complete_VIN_Vehicle_Description_Section_WriteData
        DataServices_Read_Write_complete_VIN_Vehicle_Description_Section_ConditionCheckRead
        DataServices_Read_Write_complete_VIN_Vehicle_Description_Section_ReadData
        DataServices_Read_Write_complete_VIN_World_Manufacturers_Identification_WriteData
        DataServices_Read_Write_complete_VIN_World_Manufacturers_Identification_ConditionCheckRead
        DataServices_Read_Write_complete_VIN_World_Manufacturers_Identification_ReadData
        DataServices_Bootloader_version_number_Major_release_ConditionCheckRead
        DataServices_Bootloader_version_number_Major_release_ReadData
        DataServices_Bootloader_version_number_No_functional_content_change_ConditionCheckRead
        DataServices_Bootloader_version_number_No_functional_content_change_ReadData
        DataServices_Bootloader_version_number_Minor_release_ConditionCheckRead
        DataServices_Bootloader_version_number_Minor_release_ReadData
        DataServices_Coding_for_CDS_fingerprint_codingDate_byte_1_YY_WriteData
        DataServices_Coding_for_CDS_fingerprint_codingDate_byte_1_YY_ConditionCheckRead
        DataServices_Coding_for_CDS_fingerprint_codingDate_byte_1_YY_ReadData
        DataServices_Coding_for_CDS_fingerprint_codingDate_byte_3_DD_WriteData
        DataServices_Coding_for_CDS_fingerprint_codingDate_byte_3_DD_ConditionCheckRead
        DataServices_Coding_for_CDS_fingerprint_codingDate_byte_3_DD_ReadData
        DataServices_Coding_for_CDS_fingerprint_repairShopCodeorTesterSerialNumber_byte_1_27_MSB_WriteData
        DataServices_Coding_for_CDS_fingerprint_repairShopCodeorTesterSerialNumber_byte_1_27_MSB_ConditionCheckRead
        DataServices_Coding_for_CDS_fingerprint_repairShopCodeorTesterSerialNumber_byte_1_27_MSB_ReadData
        DataServices_Coding_for_CDS_fingerprint_codingDate_byte_2_MM_WriteData
        DataServices_Coding_for_CDS_fingerprint_codingDate_byte_2_MM_ConditionCheckRead
        DataServices_Coding_for_CDS_fingerprint_codingDate_byte_2_MM_ReadData
        DataServices_Last_service_date_Month_WriteData
        DataServices_Last_service_date_Month_ConditionCheckRead
        DataServices_Last_service_date_Month_ReadData
        DataServices_Last_service_date_Day_WriteData
        DataServices_Last_service_date_Day_ConditionCheckRead
        DataServices_Last_service_date_Day_ReadData
        DataServices_Last_service_date_Year_WriteData
        DataServices_Last_service_date_Year_ConditionCheckRead
        DataServices_Last_service_date_Year_ReadData
        SecurityAccess_Unlocked_Level_4_CompareKey
        SecurityAccess_Unlocked_Level_4_GetSeed
        SecurityAccess_Unlocked_Level_3_CompareKey
        SecurityAccess_Unlocked_Level_3_GetSeed
        SecurityAccess_Unlocked_Level_2_CompareKey
        SecurityAccess_Unlocked_Level_2_GetSeed
        DataServices_Write_Level2_OEM_Key_OEM_Key_Value_WriteData
        DataServices_Write_Level4_OEM_Key_OEM_Key_Value_WriteData
        DataServices_Write_Level3_OEM_Key_OEM_Key_Value_WriteData
        DataServices_Write_Level1_OEM_Key_OEM_Key_Value_WriteData
        DataServices_EcuIdentification_Group_WriteData
        DataServices_EcuIdentification_Group_ConditionCheckRead
        DataServices_EcuIdentification_Group_ReadData
        DataServices_EcuIdentification_Execution_Package_WriteData
        DataServices_EcuIdentification_Execution_Package_ConditionCheckRead
        DataServices_EcuIdentification_Execution_Package_ReadData
        DataServices_EcuIdentification_Detail_Code_WriteData
        DataServices_EcuIdentification_Detail_Code_ConditionCheckRead
        DataServices_EcuIdentification_Detail_Code_ReadData
        DataServices_EcuIdentification_Subgroup_WriteData
        DataServices_EcuIdentification_Subgroup_ConditionCheckRead
        DataServices_EcuIdentification_Subgroup_ReadData
        DataServices_EcuIdentification_Specific_Vehicle_Code_WMI_WriteData
        DataServices_EcuIdentification_Specific_Vehicle_Code_WMI_ConditionCheckRead
        DataServices_EcuIdentification_Specific_Vehicle_Code_WMI_ReadData
        DataServices_Read_Level2_OEM_Key_written_status_Read_Level2_OEM_Key_rewrite_counter_ConditionCheckRead
        DataServices_Read_Level2_OEM_Key_written_status_Read_Level2_OEM_Key_rewrite_counter_ReadData
        DataServices_Read_Level4_OEM_Key_written_status_Read_Level4_OEM_Key_rewrite_counter_ConditionCheckRead
        DataServices_Read_Level4_OEM_Key_written_status_Read_Level4_OEM_Key_rewrite_counter_ReadData
        DataServices_Read_Level1_OEM_Key_written_status_Read_Level1_OEM_Key_rewrite_counter_ConditionCheckRead
        DataServices_Read_Level1_OEM_Key_written_status_Read_Level1_OEM_Key_rewrite_counter_ReadData
        DataServices_Read_Level3_OEM_Key_written_status_Read_Level3_OEM_Key_rewrite_counter_ConditionCheckRead
        DataServices_Read_Level3_OEM_Key_written_status_Read_Level3_OEM_Key_rewrite_counter_ReadData
        DataServices_Read_Vehicle_Security_related_events_Brute_Force_UDS_0x27_servic_Event_occurance_time_Month_1_ConditionCheckRead
        DataServices_Read_Vehicle_Security_related_events_Brute_Force_UDS_0x27_servic_Event_occurance_time_Month_1_ReadData
        DataServices_Read_Vehicle_Security_related_events_Brute_Force_UDS_0x27_servic_Event_occurance_time_Day_5_ConditionCheckRead
        DataServices_Read_Vehicle_Security_related_events_Brute_Force_UDS_0x27_servic_Event_occurance_time_Day_5_ReadData
        DataServices_Read_Vehicle_Security_related_events_Brute_Force_UDS_0x27_servic_Event_occurance_time_Day_1_ConditionCheckRead
        DataServices_Read_Vehicle_Security_related_events_Brute_Force_UDS_0x27_servic_Event_occurance_time_Day_1_ReadData
        DataServices_Read_Vehicle_Security_related_events_Brute_Force_UDS_0x27_servic_Event_occurance_time_Month_4_ConditionCheckRead
        DataServices_Read_Vehicle_Security_related_events_Brute_Force_UDS_0x27_servic_Event_occurance_time_Month_4_ReadData
        DataServices_Read_Vehicle_Security_related_events_Brute_Force_UDS_0x27_servic_Event_occurance_time_Year_4_ConditionCheckRead
        DataServices_Read_Vehicle_Security_related_events_Brute_Force_UDS_0x27_servic_Event_occurance_time_Year_4_ReadData
        DataServices_Read_Vehicle_Security_related_events_Brute_Force_UDS_0x27_servic_Event_occurance_time_Day_3_ConditionCheckRead
        DataServices_Read_Vehicle_Security_related_events_Brute_Force_UDS_0x27_servic_Event_occurance_time_Day_3_ReadData
        DataServices_Read_Vehicle_Security_related_events_Brute_Force_UDS_0x27_service_3_ConditionCheckRead
        DataServices_Read_Vehicle_Security_related_events_Brute_Force_UDS_0x27_service_3_ReadData
        DataServices_Read_Vehicle_Security_related_events_Brute_Force_UDS_0x27_servic_Event_occurance_time_Day_4_ConditionCheckRead
        DataServices_Read_Vehicle_Security_related_events_Brute_Force_UDS_0x27_servic_Event_occurance_time_Day_4_ReadData
        DataServices_Read_Vehicle_Security_related_events_Brute_Force_UDS_0x27_service_Event_occurr_0DEE2FAA_ConditionCheckRead
        DataServices_Read_Vehicle_Security_related_events_Brute_Force_UDS_0x27_service_Event_occurr_0DEE2FAA_ReadData
        DataServices_Read_Vehicle_Security_related_events_Brute_Force_UDS_0x27_service_1_ConditionCheckRead
        DataServices_Read_Vehicle_Security_related_events_Brute_Force_UDS_0x27_service_1_ReadData
        DataServices_Read_Vehicle_Security_related_events_Brute_Force_UDS_0x27_servic_Event_occurance_time_Month_5_ConditionCheckRead
        DataServices_Read_Vehicle_Security_related_events_Brute_Force_UDS_0x27_servic_Event_occurance_time_Month_5_ReadData
        DataServices_Read_Vehicle_Security_related_events_Brute_Force_UDS_0x27_service_5_ConditionCheckRead
        DataServices_Read_Vehicle_Security_related_events_Brute_Force_UDS_0x27_service_5_ReadData
        DataServices_Read_Vehicle_Security_related_events_Brute_Force_UDS_0x27_servic_Event_occurance_time_Year_3_ConditionCheckRead
        DataServices_Read_Vehicle_Security_related_events_Brute_Force_UDS_0x27_servic_Event_occurance_time_Year_3_ReadData
        DataServices_Read_Vehicle_Security_related_events_Brute_Force_UDS_0x27_servic_Event_occurance_time_Month_3_ConditionCheckRead
        DataServices_Read_Vehicle_Security_related_events_Brute_Force_UDS_0x27_servic_Event_occurance_time_Month_3_ReadData
        DataServices_Read_Vehicle_Security_related_events_Brute_Force_UDS_0x27_servic_Event_occurance_time_Year_1_ConditionCheckRead
        DataServices_Read_Vehicle_Security_related_events_Brute_Force_UDS_0x27_servic_Event_occurance_time_Year_1_ReadData
        DataServices_Read_Vehicle_Security_related_events_Brute_Force_UDS_0x27_servic_Event_occurance_time_Day_2_ConditionCheckRead
        DataServices_Read_Vehicle_Security_related_events_Brute_Force_UDS_0x27_servic_Event_occurance_time_Day_2_ReadData
        DataServices_Read_Vehicle_Security_related_events_Brute_Force_UDS_0x27_service_4_ConditionCheckRead
        DataServices_Read_Vehicle_Security_related_events_Brute_Force_UDS_0x27_service_4_ReadData
        DataServices_Read_Vehicle_Security_related_events_Brute_Force_UDS_0x27_servic_Event_occurance_time_Month_2_ConditionCheckRead
        DataServices_Read_Vehicle_Security_related_events_Brute_Force_UDS_0x27_servic_Event_occurance_time_Month_2_ReadData
        DataServices_Read_Vehicle_Security_related_events_Brute_Force_UDS_0x27_servic_Event_occurance_time_Year_5_ConditionCheckRead
        DataServices_Read_Vehicle_Security_related_events_Brute_Force_UDS_0x27_servic_Event_occurance_time_Year_5_ReadData
        DataServices_Read_Vehicle_Security_related_events_Brute_Force_UDS_0x27_service_2_ConditionCheckRead
        DataServices_Read_Vehicle_Security_related_events_Brute_Force_UDS_0x27_service_2_ReadData
        DataServices_Read_Vehicle_Security_related_events_Brute_Force_UDS_0x27_servic_Event_occurance_time_Year_2_ConditionCheckRead
        DataServices_Read_Vehicle_Security_related_events_Brute_Force_UDS_0x27_servic_Event_occurance_time_Year_2_ReadData
        DataServices_Read_Vehicle_Security_related_events_Software_configuration_inte_Event_occurance_time_Month_1_ConditionCheckRead
        DataServices_Read_Vehicle_Security_related_events_Software_configuration_inte_Event_occurance_time_Month_1_ReadData
        DataServices_Read_Vehicle_Security_related_events_Software_configuration_integrity_check_fa_B04CEA39_ConditionCheckRead
        DataServices_Read_Vehicle_Security_related_events_Software_configuration_integrity_check_fa_B04CEA39_ReadData
        DataServices_Read_Vehicle_Security_related_events_Software_configuration_integrity_check_3_ConditionCheckRead
        DataServices_Read_Vehicle_Security_related_events_Software_configuration_integrity_check_3_ReadData
        DataServices_Read_Vehicle_Security_related_events_Software_configuration_inte_Event_occurance_time_Year_5_ConditionCheckRead
        DataServices_Read_Vehicle_Security_related_events_Software_configuration_inte_Event_occurance_time_Year_5_ReadData
        DataServices_Read_Vehicle_Security_related_events_Software_configuration_integrity_check_4_ConditionCheckRead
        DataServices_Read_Vehicle_Security_related_events_Software_configuration_integrity_check_4_ReadData
        DataServices_Read_Vehicle_Security_related_events_Software_configuration_inte_Event_occurance_time_Day_3_ConditionCheckRead
        DataServices_Read_Vehicle_Security_related_events_Software_configuration_inte_Event_occurance_time_Day_3_ReadData
        DataServices_Read_Vehicle_Security_related_events_Software_configuration_inte_Event_occurance_time_Day_5_ConditionCheckRead
        DataServices_Read_Vehicle_Security_related_events_Software_configuration_inte_Event_occurance_time_Day_5_ReadData
        DataServices_Read_Vehicle_Security_related_events_Software_configuration_inte_Event_occurance_time_Day_1_ConditionCheckRead
        DataServices_Read_Vehicle_Security_related_events_Software_configuration_inte_Event_occurance_time_Day_1_ReadData
        DataServices_Read_Vehicle_Security_related_events_Software_configuration_inte_Event_occurance_time_Year_3_ConditionCheckRead
        DataServices_Read_Vehicle_Security_related_events_Software_configuration_inte_Event_occurance_time_Year_3_ReadData
        DataServices_Read_Vehicle_Security_related_events_Software_configuration_integrity_check_1_ConditionCheckRead
        DataServices_Read_Vehicle_Security_related_events_Software_configuration_integrity_check_1_ReadData
        DataServices_Read_Vehicle_Security_related_events_Software_configuration_inte_Event_occurance_time_Day_2_ConditionCheckRead
        DataServices_Read_Vehicle_Security_related_events_Software_configuration_inte_Event_occurance_time_Day_2_ReadData
        DataServices_Read_Vehicle_Security_related_events_Software_configuration_inte_Event_occurance_time_Day_4_ConditionCheckRead
        DataServices_Read_Vehicle_Security_related_events_Software_configuration_inte_Event_occurance_time_Day_4_ReadData
        DataServices_Read_Vehicle_Security_related_events_Software_configuration_inte_Event_occurance_time_Month_4_ConditionCheckRead
        DataServices_Read_Vehicle_Security_related_events_Software_configuration_inte_Event_occurance_time_Month_4_ReadData
        DataServices_Read_Vehicle_Security_related_events_Software_configuration_inte_Event_occurance_time_Month_5_ConditionCheckRead
        DataServices_Read_Vehicle_Security_related_events_Software_configuration_inte_Event_occurance_time_Month_5_ReadData
        DataServices_Read_Vehicle_Security_related_events_Software_configuration_integrity_check_5_ConditionCheckRead
        DataServices_Read_Vehicle_Security_related_events_Software_configuration_integrity_check_5_ReadData
        DataServices_Read_Vehicle_Security_related_events_Software_configuration_inte_Event_occurance_time_Month_2_ConditionCheckRead
        DataServices_Read_Vehicle_Security_related_events_Software_configuration_inte_Event_occurance_time_Month_2_ReadData
        DataServices_Read_Vehicle_Security_related_events_Software_configuration_integrity_check_2_ConditionCheckRead
        DataServices_Read_Vehicle_Security_related_events_Software_configuration_integrity_check_2_ReadData
        DataServices_Read_Vehicle_Security_related_events_Software_configuration_inte_Event_occurance_time_Month_3_ConditionCheckRead
        DataServices_Read_Vehicle_Security_related_events_Software_configuration_inte_Event_occurance_time_Month_3_ReadData
        DataServices_Read_Vehicle_Security_related_events_Software_configuration_inte_Event_occurance_time_Year_1_ConditionCheckRead
        DataServices_Read_Vehicle_Security_related_events_Software_configuration_inte_Event_occurance_time_Year_1_ReadData
        DataServices_Read_Vehicle_Security_related_events_Software_configuration_inte_Event_occurance_time_Year_2_ConditionCheckRead
        DataServices_Read_Vehicle_Security_related_events_Software_configuration_inte_Event_occurance_time_Year_2_ReadData
        DataServices_Read_Vehicle_Security_related_events_Software_configuration_inte_Event_occurance_time_Year_4_ConditionCheckRead
        DataServices_Read_Vehicle_Security_related_events_Software_configuration_inte_Event_occurance_time_Year_4_ReadData
        DataServices_Write_Level1_OEM_Key_CRC_WriteData
        DataServices_Write_Level4_OEM_Key_CRC_WriteData
        DataServices_Write_Level3_OEM_Key_CRC_WriteData
        DataServices_Write_Level2_OEM_Key_CRC_WriteData
        DataServices_BSW_version_number_Minor_release_ConditionCheckRead
        DataServices_BSW_version_number_Minor_release_ReadData
        DataServices_BSW_version_number_No_functional_content_change_ConditionCheckRead
        DataServices_BSW_version_number_No_functional_content_change_ReadData
        DataServices_BSW_version_number_Major_release_ConditionCheckRead
        DataServices_BSW_version_number_Major_release_ReadData
        DataServices_DevelopmentData_Supplier_family_code_ConditionCheckRead
        DataServices_DevelopmentData_Supplier_family_code_ReadData
        DataServices_DevelopmentData_Country_code_ConditionCheckRead
        DataServices_DevelopmentData_Country_code_ReadData
        DataServices_DevelopmentData_Supplier_code_ConditionCheckRead
        DataServices_DevelopmentData_Supplier_code_ReadData
  swc implementation YDF_DiagHandler_Implementation: behavior=YDF_DiagHandler_InternalBehavior
    code-descriptors:
      code Default: artifact-descriptors=autosar-engineering-object=category=SWSRC
